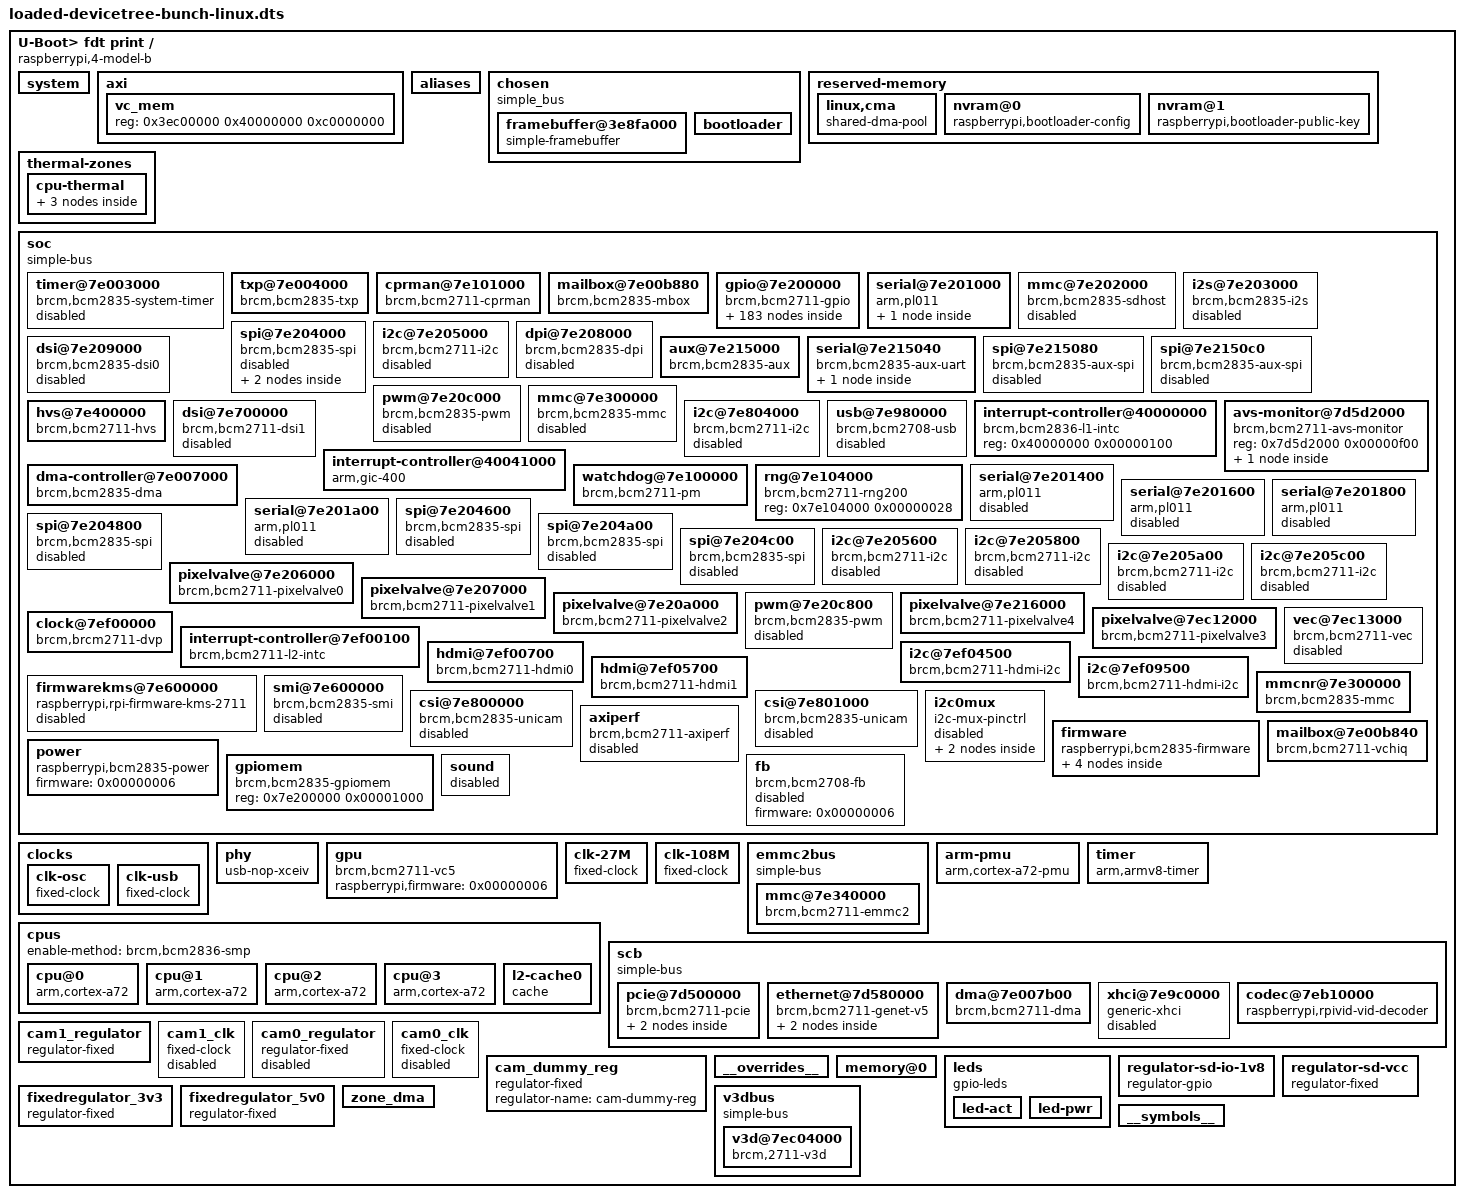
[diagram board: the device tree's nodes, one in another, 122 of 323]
U-Boot> fdt print
/ {
	memreserve = <0x30000000 0x10000000>;
	serial-number = "10000000747f32dc";
	compatible = "raspberrypi,4-model-b", "brcm,bcm2711";
	model = "Raspberry Pi 4 Model B Rev 1.4";
	#address-cells = <0x00000002>;
	#size-cells = <0x00000001>;
	interrupt-parent = <0x00000001>;
	system {
		linux,serial = <0x10000000 0x747f32dc>;
		linux,revision = <0x00c03114>;
	};
	axi {
		vc_mem {
			reg = <0x3ec00000 0x40000000 0xc0000000>;
		};
	};
	aliases {
		display0 = "/chosen/framebuffer@3e8fa000";
		serial0 = "/soc/serial@7e215040";
		serial1 = "/soc/serial@7e201000";
		emmc2bus = "/emmc2bus";
		ethernet0 = "/scb/ethernet@7d580000";
		pcie0 = "/scb/pcie@7d500000";
		blconfig = "/reserved-memory/nvram@0";
		blpubkey = "/reserved-memory/nvram@1";
		bluetooth = "/soc/serial@7e201000/bluetooth";
		aux = "/soc/aux@7e215000";
		sound = "/soc/sound";
		soc = "/soc";
		dma = "/soc/dma-controller@7e007000";
		watchdog = "/soc/watchdog@7e100000";
		random = "/soc/rng@7e104000";
		mailbox = "/soc/mailbox@7e00b880";
		gpio = "/soc/gpio@7e200000";
		uart0 = "/soc/serial@7e201000";
		uart1 = "/soc/serial@7e215040";
		sdhost = "/soc/mmc@7e202000";
		mmc = "/soc/mmc@7e300000";
		mmc1 = "/soc/mmcnr@7e300000";
		mmc0 = "/emmc2bus/mmc@7e340000";
		i2s = "/soc/i2s@7e203000";
		i2c0 = "/soc/i2c0mux/i2c@0";
		i2c1 = "/soc/i2c@7e804000";
		i2c10 = "/soc/i2c0mux/i2c@1";
		i2c = "/soc/i2c@7e804000";
		spi0 = "/soc/spi@7e204000";
		spi1 = "/soc/spi@7e215080";
		spi2 = "/soc/spi@7e2150c0";
		usb = "/soc/usb@7e980000";
		leds = "/leds";
		fb = "/soc/fb";
		thermal = "/soc/avs-monitor@7d5d2000/thermal";
		axiperf = "/soc/axiperf";
		uart2 = "/soc/serial@7e201400";
		uart3 = "/soc/serial@7e201600";
		uart4 = "/soc/serial@7e201800";
		uart5 = "/soc/serial@7e201a00";
		serial2 = "/soc/serial@7e201400";
		serial3 = "/soc/serial@7e201600";
		serial4 = "/soc/serial@7e201800";
		serial5 = "/soc/serial@7e201a00";
		mmc2 = "/soc/mmc@7e202000";
		i2c3 = "/soc/i2c@7e205600";
		i2c4 = "/soc/i2c@7e205800";
		i2c5 = "/soc/i2c@7e205a00";
		i2c6 = "/soc/i2c@7e205c00";
		i2c20 = "/soc/i2c@7ef04500";
		i2c21 = "/soc/i2c@7ef09500";
		spi3 = "/soc/spi@7e204600";
		spi4 = "/soc/spi@7e204800";
		spi5 = "/soc/spi@7e204a00";
		spi6 = "/soc/spi@7e204c00";
		phandle = <0x0000004f>;
	};
	chosen {
		ranges;
		#size-cells = <0x00000001>;
		#address-cells = <0x00000001>;
		compatible = "simple_bus";
		rng-seed = <0xc933548e 0xe2b80edd 0x7d824fa1 0x4c1fe433 0xff39cf23 0x2dc1764e 0x122f8091 0x8457ae2d 0x51d78ceb 0x2d145350 0x8de2d845 0x6ad47641 0xa8cb3f6f 0x5a67c199 0x287e0ceb 0x9471c304>;
		kaslr-seed = <0xa21e5f1d 0x71a5401c>;
		os_prefix = [00];
		overlay_prefix = "overlays/";
		rpi-boardrev-ext = <0x00000000>;
		log = <0x3ff80000 0x0007ffe0>;
		stdout-path = "serial0:115200n8";
		bootargs = "coherent_pool=1M 8250.nr_uarts=1 snd_bcm2835.enable_headphones=0 snd_bcm2835.enable_hdmi=0 video=HDMI-A-1:1024x768M@70 smsc95xx.macaddr=E4:5F:01:60:B9:C2 vc_mem.mem_base=0x3ec00000 vc_mem.mem_size=0x40000000  dwc_otg.lpm_enable=0 console=ttyS0,115200  net.ifnames=0";
		phandle = <0x00000050>;
		framebuffer@3e8fa000 {
			status = "okay";
			compatible = "simple-framebuffer";
			format = "a8r8g8b8";
			stride = <0x00001000>;
			height = <0x00000300>;
			width = <0x00000400>;
			reg = <0x3e8fa000 0x00300000>;
		};
		bootloader {
			boot-mode = <0x00000001>;
			version = "0b7b6f28b0a25311e6d75518aec0e29ecfb36ec0";
			capabilities = <0x0000007f>;
			update-timestamp = <0x6628b441>;
			build-timestamp = <0x661fc5d8>;
			tryboot = <0x00000000>;
			rsts = <0x00001000>;
			partition = <0x00000000>;
		};
	};
	reserved-memory {
		#address-cells = <0x00000002>;
		#size-cells = <0x00000001>;
		ranges;
		phandle = <0x00000056>;
		linux,cma {
			compatible = "shared-dma-pool";
			size = <0x20000000>;
			reusable;
			linux,cma-default;
			alloc-ranges = <0x00000000 0x00000000 0x30000000>;
			phandle = <0x00000057>;
		};
		nvram@0 {
			compatible = "raspberrypi,bootloader-config", "nvmem-rmem";
			#address-cells = <0x00000001>;
			#size-cells = <0x00000001>;
			reg = <0x00000000 0x3ef64640 0x00000036>;
			no-map;
			status = "okay";
			phandle = <0x00000058>;
		};
		nvram@1 {
			compatible = "raspberrypi,bootloader-public-key", "nvmem-rmem";
			#address-cells = <0x00000001>;
			#size-cells = <0x00000001>;
			reg = <0x00000000 0x3ef64400 0x00000200>;
			no-map;
			status = "okay";
			phandle = <0x00000059>;
		};
	};
	thermal-zones {
		cpu-thermal {
			polling-delay-passive = <0x00000000>;
			polling-delay = <0x000003e8>;
			coefficients = <0xfffffe19 0x000641b8>;
			thermal-sensors = <0x00000002>;
			phandle = <0x0000005a>;
			trips {
				phandle = <0x0000005b>;
				cpu-crit {
					temperature = <0x0001adb0>;
					hysteresis = <0x00000000>;
					type = "critical";
				};
			};
			cooling-maps {
				phandle = <0x0000005c>;
			};
		};
	};
	soc {
		compatible = "simple-bus";
		#address-cells = <0x00000001>;
		#size-cells = <0x00000001>;
		ranges = <0x7e000000 0x00000000 0xfe000000 0x01800000 0x7c000000 0x00000000 0xfc000000 0x02000000 0x40000000 0x00000000 0xff800000 0x00800000>;
		dma-ranges = <0xc0000000 0x00000000 0x00000000 0x40000000 0x7c000000 0x00000000 0xfc000000 0x03800000>;
		phandle = <0x0000005d>;
		timer@7e003000 {
			compatible = "brcm,bcm2835-system-timer";
			reg = <0x7e003000 0x00001000>;
			interrupts = <0x00000000 0x00000040 0x00000004 0x00000000 0x00000041 0x00000004 0x00000000 0x00000042 0x00000004 0x00000000 0x00000043 0x00000004>;
			clock-frequency = <0x000f4240>;
			status = "disabled";
			phandle = <0x0000005e>;
		};
		txp@7e004000 {
			compatible = "brcm,bcm2835-txp";
			reg = <0x7e004000 0x00000020>;
			interrupts = <0x00000000 0x0000004b 0x00000004>;
			status = "okay";
			phandle = <0x0000005f>;
		};
		cprman@7e101000 {
			compatible = "brcm,bcm2711-cprman";
			#clock-cells = <0x00000001>;
			reg = <0x7e101000 0x00002000>;
			clocks = <0x00000003 0x00000004 0x00000000 0x00000004 0x00000001 0x00000004 0x00000002 0x00000005 0x00000000 0x00000005 0x00000001 0x00000005 0x00000002>;
			firmware = <0x00000006>;
			phandle = <0x00000008>;
		};
		mailbox@7e00b880 {
			compatible = "brcm,bcm2835-mbox";
			reg = <0x7e00b880 0x00000040>;
			interrupts = <0x00000000 0x00000021 0x00000004>;
			#mbox-cells = <0x00000000>;
			phandle = <0x00000035>;
		};
		gpio@7e200000 {
			compatible = "brcm,bcm2711-gpio";
			reg = <0x7e200000 0x000000b4>;
			interrupts = <0x00000000 0x00000071 0x00000004 0x00000000 0x00000072 0x00000004>;
			gpio-controller;
			#gpio-cells = <0x00000002>;
			interrupt-controller;
			#interrupt-cells = <0x00000002>;
			gpio-ranges = <0x00000007 0x00000000 0x00000000 0x0000003a>;
			gpio-line-names = "ID_SDA", "ID_SCL", "GPIO2", "GPIO3", "GPIO4", "GPIO5", "GPIO6", "GPIO7", "GPIO8", "GPIO9", "GPIO10", "GPIO11", "GPIO12", "GPIO13", "GPIO14", "GPIO15", "GPIO16", "GPIO17", "GPIO18", "GPIO19", "GPIO20", "GPIO21", "GPIO22", "GPIO23", "GPIO24", "GPIO25", "GPIO26", "GPIO27", "RGMII_MDIO", "RGMIO_MDC", "CTS0", "RTS0", "TXD0", "RXD0", "SD1_CLK", "SD1_CMD", "SD1_DATA0", "SD1_DATA1", "SD1_DATA2", "SD1_DATA3", "PWM0_MISO", "PWM1_MOSI", "STATUS_LED_G_CLK", "SPIFLASH_CE_N", "SDA0", "SCL0", "RGMII_RXCLK", "RGMII_RXCTL", "RGMII_RXD0", "RGMII_RXD1", "RGMII_RXD2", "RGMII_RXD3", "RGMII_TXCLK", "RGMII_TXCTL", "RGMII_TXD0", "RGMII_TXD1", "RGMII_TXD2", "RGMII_TXD3";
			phandle = <0x00000007>;
			dpi-gpio0 {
				brcm,pins = <0x00000000 0x00000001 0x00000002 0x00000003 0x00000004 0x00000005 0x00000006 0x00000007 0x00000008 0x00000009 0x0000000a 0x0000000b 0x0000000c 0x0000000d 0x0000000e 0x0000000f 0x00000010 0x00000011 0x00000012 0x00000013 0x00000014 0x00000015 0x00000016 0x00000017 0x00000018 0x00000019 0x0000001a 0x0000001b>;
				brcm,function = <0x00000006>;
				phandle = <0x00000060>;
			};
			emmc-gpio22 {
				brcm,pins = <0x00000016 0x00000017 0x00000018 0x00000019 0x0000001a 0x0000001b>;
				brcm,function = <0x00000007>;
				phandle = <0x00000061>;
			};
			emmc-gpio34 {
				brcm,pins = <0x00000022 0x00000023 0x00000024 0x00000025 0x00000026 0x00000027>;
				brcm,function = <0x00000007>;
				brcm,pull = <0x00000000 0x00000002 0x00000002 0x00000002 0x00000002 0x00000002>;
				phandle = <0x00000062>;
			};
			emmc-gpio48 {
				brcm,pins = <0x00000030 0x00000031 0x00000032 0x00000033 0x00000034 0x00000035>;
				brcm,function = <0x00000007>;
				phandle = <0x00000013>;
			};
			gpclk0-gpio4 {
				brcm,pins = <0x00000004>;
				brcm,function = <0x00000004>;
				phandle = <0x00000063>;
			};
			gpclk1-gpio5 {
				brcm,pins = <0x00000005>;
				brcm,function = <0x00000004>;
				phandle = <0x00000064>;
			};
			gpclk1-gpio42 {
				brcm,pins = <0x0000002a>;
				brcm,function = <0x00000004>;
				phandle = <0x00000065>;
			};
			gpclk1-gpio44 {
				brcm,pins = <0x0000002c>;
				brcm,function = <0x00000004>;
				phandle = <0x00000066>;
			};
			gpclk2-gpio6 {
				brcm,pins = <0x00000006>;
				brcm,function = <0x00000004>;
				phandle = <0x00000067>;
			};
			gpclk2-gpio43 {
				brcm,pins = <0x0000002b>;
				brcm,function = <0x00000004>;
				brcm,pull = <0x00000000>;
				phandle = <0x00000068>;
			};
			i2c0if-gpio0 {
				brcm,pins = <0x00000000 0x00000001>;
				brcm,function = <0x00000004>;
				phandle = <0x00000033>;
			};
			i2c0if-gpio28 {
				brcm,pins = <0x0000001c 0x0000001d>;
				brcm,function = <0x00000004>;
				phandle = <0x00000069>;
			};
			i2c0if-gpio44 {
				brcm,pins = <0x0000002c 0x0000002d>;
				brcm,function = <0x00000005>;
				phandle = <0x00000034>;
			};
			i2c1-gpio2 {
				brcm,pins = <0x00000002 0x00000003>;
				brcm,function = <0x00000004>;
				phandle = <0x0000006a>;
			};
			i2c1-gpio44 {
				brcm,pins = <0x0000002c 0x0000002d>;
				brcm,function = <0x00000006>;
				phandle = <0x0000006b>;
			};
			jtag-gpio22 {
				brcm,pins = <0x00000016 0x00000017 0x00000018 0x00000019 0x0000001a 0x0000001b>;
				brcm,function = <0x00000003>;
				phandle = <0x0000006c>;
			};
			pcm-gpio18 {
				brcm,pins = <0x00000012 0x00000013 0x00000014 0x00000015>;
				brcm,function = <0x00000004>;
				phandle = <0x0000006d>;
			};
			pcm-gpio28 {
				brcm,pins = <0x0000001c 0x0000001d 0x0000001e 0x0000001f>;
				brcm,function = <0x00000006>;
				phandle = <0x0000006e>;
			};
			sdhost-gpio48 {
				brcm,pins = <0x00000030 0x00000031 0x00000032 0x00000033 0x00000034 0x00000035>;
				brcm,function = <0x00000004>;
				phandle = <0x0000006f>;
			};
			spi0-gpio7 {
				brcm,pins = <0x00000007 0x00000008 0x00000009 0x0000000a 0x0000000b>;
				brcm,function = <0x00000004>;
				phandle = <0x00000070>;
			};
			spi0-gpio35 {
				brcm,pins = <0x00000023 0x00000024 0x00000025 0x00000026 0x00000027>;
				brcm,function = <0x00000004>;
				phandle = <0x00000071>;
			};
			spi1-gpio16 {
				brcm,pins = <0x00000010 0x00000011 0x00000012 0x00000013 0x00000014 0x00000015>;
				brcm,function = <0x00000003>;
				phandle = <0x00000072>;
			};
			spi2-gpio40 {
				brcm,pins = <0x00000028 0x00000029 0x0000002a 0x0000002b 0x0000002c 0x0000002d>;
				brcm,function = <0x00000003>;
				phandle = <0x00000073>;
			};
			uart0-gpio14 {
				brcm,pins = <0x0000000e 0x0000000f>;
				brcm,function = <0x00000004>;
				phandle = <0x00000074>;
			};
			uart0-ctsrts-gpio16 {
				brcm,pins = <0x00000010 0x00000011>;
				brcm,function = <0x00000007>;
				phandle = <0x00000075>;
			};
			uart0-ctsrts-gpio30 {
				brcm,pins = <0x0000001e 0x0000001f>;
				brcm,function = <0x00000007>;
				brcm,pull = <0x00000002 0x00000000>;
				phandle = <0x00000076>;
			};
			uart0-gpio32 {
				brcm,pins = <0x00000020 0x00000021>;
				brcm,function = <0x00000007>;
				brcm,pull = <0x00000000 0x00000002>;
				phandle = <0x00000077>;
			};
			uart0-gpio36 {
				brcm,pins = <0x00000024 0x00000025>;
				brcm,function = <0x00000006>;
				phandle = <0x00000078>;
			};
			uart0-ctsrts-gpio38 {
				brcm,pins = <0x00000026 0x00000027>;
				brcm,function = <0x00000006>;
				phandle = <0x00000079>;
			};
			uart1-gpio14 {
				brcm,pins = <0x0000000e 0x0000000f>;
				brcm,function = <0x00000002>;
				phandle = <0x0000007a>;
			};
			uart1-ctsrts-gpio16 {
				brcm,pins = <0x00000010 0x00000011>;
				brcm,function = <0x00000002>;
				phandle = <0x0000007b>;
			};
			uart1-gpio32 {
				brcm,pins = <0x00000020 0x00000021>;
				brcm,function = <0x00000002>;
				phandle = <0x0000007c>;
			};
			uart1-ctsrts-gpio30 {
				brcm,pins = <0x0000001e 0x0000001f>;
				brcm,function = <0x00000002>;
				phandle = <0x0000007d>;
			};
			uart1-gpio40 {
				brcm,pins = <0x00000028 0x00000029>;
				brcm,function = <0x00000002>;
				phandle = <0x0000007e>;
			};
			uart1-ctsrts-gpio42 {
				brcm,pins = <0x0000002a 0x0000002b>;
				brcm,function = <0x00000002>;
				phandle = <0x0000007f>;
			};
			gpclk0-gpio49 {
				phandle = <0x00000080>;
				pin-gpclk {
					pins = "gpio49";
					function = "alt1";
					bias-disable;
				};
			};
			gpclk1-gpio50 {
				phandle = <0x00000081>;
				pin-gpclk {
					pins = "gpio50";
					function = "alt1";
					bias-disable;
				};
			};
			gpclk2-gpio51 {
				phandle = <0x00000082>;
				pin-gpclk {
					pins = "gpio51";
					function = "alt1";
					bias-disable;
				};
			};
			i2c0if-gpio46 {
				phandle = <0x00000083>;
				pin-sda {
					function = "alt0";
					pins = "gpio46";
					bias-pull-up;
				};
				pin-scl {
					function = "alt0";
					pins = "gpio47";
					bias-disable;
				};
			};
			i2c1-gpio46 {
				phandle = <0x00000084>;
				pin-sda {
					function = "alt1";
					pins = "gpio46";
					bias-pull-up;
				};
				pin-scl {
					function = "alt1";
					pins = "gpio47";
					bias-disable;
				};
			};
			i2c3-gpio2 {
				phandle = <0x00000085>;
				pin-sda {
					function = "alt5";
					pins = "gpio2";
					bias-pull-up;
				};
				pin-scl {
					function = "alt5";
					pins = "gpio3";
					bias-disable;
				};
			};
			i2c3-gpio4 {
				phandle = <0x00000086>;
				pin-sda {
					function = "alt5";
					pins = "gpio4";
					bias-pull-up;
				};
				pin-scl {
					function = "alt5";
					pins = "gpio5";
					bias-disable;
				};
			};
			i2c4-gpio6 {
				phandle = <0x00000087>;
				pin-sda {
					function = "alt5";
					pins = "gpio6";
					bias-pull-up;
				};
				pin-scl {
					function = "alt5";
					pins = "gpio7";
					bias-disable;
				};
			};
			i2c4-gpio8 {
				phandle = <0x00000088>;
				pin-sda {
					function = "alt5";
					pins = "gpio8";
					bias-pull-up;
				};
				pin-scl {
					function = "alt5";
					pins = "gpio9";
					bias-disable;
				};
			};
			i2c5-gpio10 {
				phandle = <0x00000089>;
				pin-sda {
					function = "alt5";
					pins = "gpio10";
					bias-pull-up;
				};
				pin-scl {
					function = "alt5";
					pins = "gpio11";
					bias-disable;
				};
			};
			i2c5-gpio12 {
				phandle = <0x0000008a>;
				pin-sda {
					function = "alt5";
					pins = "gpio12";
					bias-pull-up;
				};
				pin-scl {
					function = "alt5";
					pins = "gpio13";
					bias-disable;
				};
			};
			i2c6-gpio0 {
				phandle = <0x0000008b>;
				pin-sda {
					function = "alt5";
					pins = "gpio0";
					bias-pull-up;
				};
				pin-scl {
					function = "alt5";
					pins = "gpio1";
					bias-disable;
				};
			};
			i2c6-gpio22 {
				phandle = <0x0000008c>;
				pin-sda {
					function = "alt5";
					pins = "gpio22";
					bias-pull-up;
				};
				pin-scl {
					function = "alt5";
					pins = "gpio23";
					bias-disable;
				};
			};
			i2c-slave-gpio8 {
				phandle = <0x0000008d>;
				pins-i2c-slave {
					pins = "gpio8", "gpio9", "gpio10", "gpio11";
					function = "alt3";
				};
			};
			jtag-gpio48 {
				phandle = <0x0000008e>;
				pins-jtag {
					pins = "gpio48", "gpio49", "gpio50", "gpio51", "gpio52", "gpio53";
					function = "alt4";
				};
			};
			mii-gpio28 {
				phandle = <0x0000008f>;
				pins-mii {
					pins = "gpio28", "gpio29", "gpio30", "gpio31";
					function = "alt4";
				};
			};
			mii-gpio36 {
				phandle = <0x00000090>;
				pins-mii {
					pins = "gpio36", "gpio37", "gpio38", "gpio39";
					function = "alt5";
				};
			};
			pcm-gpio50 {
				phandle = <0x00000091>;
				pins-pcm {
					pins = "gpio50", "gpio51", "gpio52", "gpio53";
					function = "alt2";
				};
			};
			pwm0-0-gpio12 {
				phandle = <0x00000092>;
				pin-pwm {
					pins = "gpio12";
					function = "alt0";
					bias-disable;
				};
			};
			pwm0-0-gpio18 {
				phandle = <0x00000093>;
				pin-pwm {
					pins = "gpio18";
					function = "alt5";
					bias-disable;
				};
			};
			pwm1-0-gpio40 {
				phandle = <0x00000028>;
				pin-pwm {
					pins = "gpio40";
					function = "alt0";
					bias-disable;
				};
			};
			pwm0-1-gpio13 {
				phandle = <0x00000094>;
				pin-pwm {
					pins = "gpio13";
					function = "alt0";
					bias-disable;
				};
			};
			pwm0-1-gpio19 {
				phandle = <0x00000095>;
				pin-pwm {
					pins = "gpio19";
					function = "alt5";
					bias-disable;
				};
			};
			pwm1-1-gpio41 {
				phandle = <0x00000029>;
				pin-pwm {
					pins = "gpio41";
					function = "alt0";
					bias-disable;
				};
			};
			pwm0-1-gpio45 {
				phandle = <0x00000096>;
				pin-pwm {
					pins = "gpio45";
					function = "alt0";
					bias-disable;
				};
			};
			pwm0-0-gpio52 {
				phandle = <0x00000097>;
				pin-pwm {
					pins = "gpio52";
					function = "alt1";
					bias-disable;
				};
			};
			pwm0-1-gpio53 {
				phandle = <0x00000098>;
				pin-pwm {
					pins = "gpio53";
					function = "alt1";
					bias-disable;
				};
			};
			rgmii-gpio35 {
				phandle = <0x00000099>;
				pin-start-stop {
					pins = "gpio35";
					function = "alt4";
				};
				pin-rx-ok {
					pins = "gpio36";
					function = "alt4";
				};
			};
			rgmii-irq-gpio34 {
				phandle = <0x0000009a>;
				pin-irq {
					pins = "gpio34";
					function = "alt5";
				};
			};
			rgmii-irq-gpio39 {
				phandle = <0x0000009b>;
				pin-irq {
					pins = "gpio39";
					function = "alt4";
				};
			};
			rgmii-mdio-gpio28 {
				phandle = <0x0000009c>;
				pins-mdio {
					pins = "gpio28", "gpio29";
					function = "alt5";
				};
			};
			rgmii-mdio-gpio37 {
				phandle = <0x0000009d>;
				pins-mdio {
					pins = "gpio37", "gpio38";
					function = "alt4";
				};
			};
			spi0-gpio46 {
				phandle = <0x0000009e>;
				pins-spi {
					pins = "gpio46", "gpio47", "gpio48", "gpio49";
					function = "alt2";
				};
			};
			spi2-gpio46 {
				phandle = <0x0000009f>;
				pins-spi {
					pins = "gpio46", "gpio47", "gpio48", "gpio49", "gpio50";
					function = "alt5";
				};
			};
			spi3-gpio0 {
				phandle = <0x000000a0>;
				pins-spi {
					pins = "gpio0", "gpio1", "gpio2", "gpio3";
					function = "alt3";
				};
			};
			spi4-gpio4 {
				phandle = <0x000000a1>;
				pins-spi {
					pins = "gpio4", "gpio5", "gpio6", "gpio7";
					function = "alt3";
				};
			};
			spi5-gpio12 {
				phandle = <0x000000a2>;
				pins-spi {
					pins = "gpio12", "gpio13", "gpio14", "gpio15";
					function = "alt3";
				};
			};
			spi6-gpio18 {
				phandle = <0x000000a3>;
				pins-spi {
					pins = "gpio18", "gpio19", "gpio20", "gpio21";
					function = "alt3";
				};
			};
			uart2-gpio0 {
				phandle = <0x000000a4>;
				pin-tx {
					pins = "gpio0";
					function = "alt4";
					bias-disable;
				};
				pin-rx {
					pins = "gpio1";
					function = "alt4";
					bias-pull-up;
				};
			};
			uart2-ctsrts-gpio2 {
				phandle = <0x000000a5>;
				pin-cts {
					pins = "gpio2";
					function = "alt4";
					bias-pull-up;
				};
				pin-rts {
					pins = "gpio3";
					function = "alt4";
					bias-disable;
				};
			};
			uart3-gpio4 {
				phandle = <0x000000a6>;
				pin-tx {
					pins = "gpio4";
					function = "alt4";
					bias-disable;
				};
				pin-rx {
					pins = "gpio5";
					function = "alt4";
					bias-pull-up;
				};
			};
			uart3-ctsrts-gpio6 {
				phandle = <0x000000a7>;
				pin-cts {
					pins = "gpio6";
					function = "alt4";
					bias-pull-up;
				};
				pin-rts {
					pins = "gpio7";
					function = "alt4";
					bias-disable;
				};
			};
			uart4-gpio8 {
				phandle = <0x000000a8>;
				pin-tx {
					pins = "gpio8";
					function = "alt4";
					bias-disable;
				};
				pin-rx {
					pins = "gpio9";
					function = "alt4";
					bias-pull-up;
				};
			};
			uart4-ctsrts-gpio10 {
				phandle = <0x000000a9>;
				pin-cts {
					pins = "gpio10";
					function = "alt4";
					bias-pull-up;
				};
				pin-rts {
					pins = "gpio11";
					function = "alt4";
					bias-disable;
				};
			};
			uart5-gpio12 {
				phandle = <0x000000aa>;
				pin-tx {
					pins = "gpio12";
					function = "alt4";
					bias-disable;
				};
				pin-rx {
					pins = "gpio13";
					function = "alt4";
					bias-pull-up;
				};
			};
			uart5-ctsrts-gpio14 {
				phandle = <0x000000ab>;
				pin-cts {
					pins = "gpio14";
					function = "alt4";
					bias-pull-up;
				};
				pin-rts {
					pins = "gpio15";
					function = "alt4";
					bias-disable;
				};
			};
			dpi_18bit_cpadhi_gpio0 {
				brcm,pins = <0x00000000 0x00000001 0x00000002 0x00000003 0x00000004 0x00000005 0x00000006 0x00000007 0x00000008 0x00000009 0x0000000c 0x0000000d 0x0000000e 0x0000000f 0x00000010 0x00000011 0x00000014 0x00000015 0x00000016 0x00000017 0x00000018 0x00000019>;
				brcm,function = <0x00000006>;
				brcm,pull = <0x00000000>;
				phandle = <0x000000ac>;
			};
			dpi_18bit_cpadhi_gpio2 {
				brcm,pins = <0x00000002 0x00000003 0x00000004 0x00000005 0x00000006 0x00000007 0x00000008 0x00000009 0x0000000c 0x0000000d 0x0000000e 0x0000000f 0x00000010 0x00000011 0x00000014 0x00000015 0x00000016 0x00000017 0x00000018 0x00000019>;
				brcm,function = <0x00000006>;
				phandle = <0x000000ad>;
			};
			dpi_18bit_gpio0 {
				brcm,pins = <0x00000000 0x00000001 0x00000002 0x00000003 0x00000004 0x00000005 0x00000006 0x00000007 0x00000008 0x00000009 0x0000000a 0x0000000b 0x0000000c 0x0000000d 0x0000000e 0x0000000f 0x00000010 0x00000011 0x00000012 0x00000013 0x00000014 0x00000015>;
				brcm,function = <0x00000006>;
				phandle = <0x000000ae>;
			};
			dpi_18bit_gpio2 {
				brcm,pins = <0x00000002 0x00000003 0x00000004 0x00000005 0x00000006 0x00000007 0x00000008 0x00000009 0x0000000a 0x0000000b 0x0000000c 0x0000000d 0x0000000e 0x0000000f 0x00000010 0x00000011 0x00000012 0x00000013 0x00000014 0x00000015>;
				brcm,function = <0x00000006>;
				phandle = <0x000000af>;
			};
			dpi_16bit_gpio0 {
				brcm,pins = <0x00000000 0x00000001 0x00000002 0x00000003 0x00000004 0x00000005 0x00000006 0x00000007 0x00000008 0x00000009 0x0000000a 0x0000000b 0x0000000c 0x0000000d 0x0000000e 0x0000000f 0x00000010 0x00000011 0x00000012 0x00000013>;
				brcm,function = <0x00000006>;
				phandle = <0x000000b0>;
			};
			dpi_16bit_gpio2 {
				brcm,pins = <0x00000002 0x00000003 0x00000004 0x00000005 0x00000006 0x00000007 0x00000008 0x00000009 0x0000000a 0x0000000b 0x0000000c 0x0000000d 0x0000000e 0x0000000f 0x00000010 0x00000011 0x00000012 0x00000013>;
				brcm,function = <0x00000006>;
				phandle = <0x000000b1>;
			};
			dpi_16bit_cpadhi_gpio0 {
				brcm,pins = <0x00000000 0x00000001 0x00000002 0x00000003 0x00000004 0x00000005 0x00000006 0x00000007 0x00000008 0x0000000c 0x0000000d 0x0000000e 0x0000000f 0x00000010 0x00000011 0x00000014 0x00000015 0x00000016 0x00000017 0x00000018>;
				brcm,function = <0x00000006>;
				phandle = <0x000000b2>;
			};
			dpi_16bit_cpadhi_gpio2 {
				brcm,pins = <0x00000002 0x00000003 0x00000004 0x00000005 0x00000006 0x00000007 0x00000008 0x0000000c 0x0000000d 0x0000000e 0x0000000f 0x00000010 0x00000011 0x00000014 0x00000015 0x00000016 0x00000017 0x00000018>;
				brcm,function = <0x00000006>;
				phandle = <0x000000b3>;
			};
			gpioout {
				brcm,pins = <0x00000006>;
				brcm,function = <0x00000001>;
				phandle = <0x000000b4>;
			};
			alt0 {
				brcm,pins = <0x00000004 0x00000005 0x00000007 0x00000008 0x00000009 0x0000000a 0x0000000b>;
				brcm,function = <0x00000004>;
				phandle = <0x000000b5>;
			};
			spi0_pins {
				brcm,pins = <0x00000009 0x0000000a 0x0000000b>;
				brcm,function = <0x00000004>;
				phandle = <0x0000000e>;
			};
			spi0_cs_pins {
				brcm,pins = <0x00000008 0x00000007>;
				brcm,function = <0x00000001>;
				phandle = <0x0000000f>;
			};
			spi3_pins {
				brcm,pins = <0x00000001 0x00000002 0x00000003>;
				brcm,function = <0x00000007>;
				phandle = <0x0000001c>;
			};
			spi3_cs_pins {
				brcm,pins = <0x00000000 0x00000018>;
				brcm,function = <0x00000001>;
				phandle = <0x0000001d>;
			};
			spi4_pins {
				brcm,pins = <0x00000005 0x00000006 0x00000007>;
				brcm,function = <0x00000007>;
				phandle = <0x0000001e>;
			};
			spi4_cs_pins {
				brcm,pins = <0x00000004 0x00000019>;
				brcm,function = <0x00000001>;
				phandle = <0x0000001f>;
			};
			spi5_pins {
				brcm,pins = <0x0000000d 0x0000000e 0x0000000f>;
				brcm,function = <0x00000007>;
				phandle = <0x00000020>;
			};
			spi5_cs_pins {
				brcm,pins = <0x0000000c 0x0000001a>;
				brcm,function = <0x00000001>;
				phandle = <0x00000021>;
			};
			spi6_pins {
				brcm,pins = <0x00000013 0x00000014 0x00000015>;
				brcm,function = <0x00000007>;
				phandle = <0x00000022>;
			};
			spi6_cs_pins {
				brcm,pins = <0x00000012 0x0000001b>;
				brcm,function = <0x00000001>;
				phandle = <0x00000023>;
			};
			i2c0 {
				brcm,pins = <0x00000000 0x00000001>;
				brcm,function = <0x00000004>;
				brcm,pull = <0x00000002>;
				phandle = <0x000000b6>;
			};
			i2c1 {
				brcm,pins = <0x00000002 0x00000003>;
				brcm,function = <0x00000004>;
				brcm,pull = <0x00000002>;
				phandle = <0x00000015>;
			};
			i2c3 {
				brcm,pins = <0x00000004 0x00000005>;
				brcm,function = <0x00000002>;
				brcm,pull = <0x00000002>;
				phandle = <0x00000024>;
			};
			i2c4 {
				brcm,pins = <0x00000008 0x00000009>;
				brcm,function = <0x00000002>;
				brcm,pull = <0x00000002>;
				phandle = <0x00000025>;
			};
			i2c5 {
				brcm,pins = <0x0000000c 0x0000000d>;
				brcm,function = <0x00000002>;
				brcm,pull = <0x00000002>;
				phandle = <0x00000026>;
			};
			i2c6 {
				brcm,pins = <0x00000016 0x00000017>;
				brcm,function = <0x00000002>;
				brcm,pull = <0x00000002>;
				phandle = <0x00000027>;
			};
			i2s {
				brcm,pins = <0x00000012 0x00000013 0x00000014 0x00000015>;
				brcm,function = <0x00000004>;
				phandle = <0x0000000d>;
			};
			sdio_pins {
				brcm,pins = <0x00000022 0x00000023 0x00000024 0x00000025 0x00000026 0x00000027>;
				brcm,function = <0x00000007>;
				brcm,pull = <0x00000000 0x00000002 0x00000002 0x00000002 0x00000002 0x00000002>;
				phandle = <0x00000031>;
			};
			uart2_pins {
				brcm,pins = <0x00000000 0x00000001>;
				brcm,function = <0x00000003>;
				brcm,pull = <0x00000000 0x00000002>;
				phandle = <0x00000018>;
			};
			uart3_pins {
				brcm,pins = <0x00000004 0x00000005>;
				brcm,function = <0x00000003>;
				brcm,pull = <0x00000000 0x00000002>;
				phandle = <0x00000019>;
			};
			uart4_pins {
				brcm,pins = <0x00000008 0x00000009>;
				brcm,function = <0x00000003>;
				brcm,pull = <0x00000000 0x00000002>;
				phandle = <0x0000001a>;
			};
			uart5_pins {
				brcm,pins = <0x0000000c 0x0000000d>;
				brcm,function = <0x00000003>;
				brcm,pull = <0x00000000 0x00000002>;
				phandle = <0x0000001b>;
			};
			bt_pins {
				brcm,pins = "-";
				brcm,function = <0x00000000>;
				brcm,pull = <0x00000002>;
				phandle = <0x0000000a>;
			};
			uart0_pins {
				brcm,pins = <0x0000001e 0x0000001f 0x00000020 0x00000021>;
				brcm,function = <0x00000007>;
				brcm,pull = <0x00000002 0x00000000 0x00000000 0x00000002>;
				phandle = <0x00000009>;
			};
			uart1_pins {
				brcm,pins;
				brcm,function;
				brcm,pull;
				phandle = <0x00000012>;
			};
			uart1_bt_pins {
				brcm,pins = <0x00000020 0x00000021 0x0000001e 0x0000001f>;
				brcm,function = <0x00000002>;
				brcm,pull = <0x00000000 0x00000002 0x00000002 0x00000000>;
				phandle = <0x000000b7>;
			};
			audio_pins {
				brcm,pins = <0x00000028 0x00000029>;
				brcm,function = <0x00000004>;
				brcm,pull = <0x00000000>;
				phandle = <0x00000036>;
			};
		};
		serial@7e201000 {
			compatible = "arm,pl011", "arm,primecell";
			reg = <0x7e201000 0x00000200>;
			interrupts = <0x00000000 0x00000079 0x00000004>;
			clocks = <0x00000008 0x00000013 0x00000008 0x00000014>;
			clock-names = "uartclk", "apb_pclk";
			arm,primecell-periphid = <0x00241011>;
			status = "okay";
			cts-event-workaround;
			pinctrl-names = "default";
			pinctrl-0 = <0x00000009 0x0000000a>;
			uart-has-rtscts;
			skip-init;
			phandle = <0x00000043>;
			bluetooth {
				compatible = "brcm,bcm43438-bt";
				max-speed = <0x002dc6c0>;
				shutdown-gpios = <0x0000000b 0x00000000 0x00000000>;
				local-bd-address = [68 13 ca 01 5f e4];
				fallback-bd-address;
				status = "okay";
				phandle = <0x00000041>;
			};
		};
		mmc@7e202000 {
			compatible = "brcm,bcm2835-sdhost";
			reg = <0x7e202000 0x00000100>;
			interrupts = <0x00000000 0x00000078 0x00000004>;
			clocks = <0x00000008 0x00000014>;
			status = "disabled";
			dmas = <0x0000000c 0x2000000d>;
			dma-names = "rx-tx";
			bus-width = <0x00000004>;
			brcm,overclock-50 = <0x00000000>;
			brcm,pio-limit = <0x00000001>;
			firmware = <0x00000006>;
			phandle = <0x0000004b>;
		};
		i2s@7e203000 {
			compatible = "brcm,bcm2835-i2s";
			reg = <0x7e203000 0x00000024>;
			clocks = <0x00000008 0x0000001f>;
			status = "disabled";
			#sound-dai-cells = <0x00000000>;
			dmas = <0x0000000c 0x00000002 0x0000000c 0x00000003>;
			dma-names = "tx", "rx";
			pinctrl-names = "default";
			pinctrl-0 = <0x0000000d>;
			phandle = <0x00000045>;
		};
		spi@7e204000 {
			compatible = "brcm,bcm2835-spi";
			reg = <0x7e204000 0x00000200>;
			interrupts = <0x00000000 0x00000076 0x00000004>;
			clocks = <0x00000008 0x00000014>;
			#address-cells = <0x00000001>;
			#size-cells = <0x00000000>;
			status = "disabled";
			dmas = <0x0000000c 0x00000006 0x0000000c 0x00000007>;
			dma-names = "tx", "rx";
			pinctrl-names = "default";
			pinctrl-0 = <0x0000000e 0x0000000f>;
			cs-gpios = <0x00000007 0x00000008 0x00000001 0x00000007 0x00000007 0x00000001>;
			phandle = <0x00000046>;
			spidev@0 {
				compatible = "spidev";
				reg = <0x00000000>;
				#address-cells = <0x00000001>;
				#size-cells = <0x00000000>;
				spi-max-frequency = <0x07735940>;
				phandle = <0x000000b8>;
			};
			spidev@1 {
				compatible = "spidev";
				reg = <0x00000001>;
				#address-cells = <0x00000001>;
				#size-cells = <0x00000000>;
				spi-max-frequency = <0x07735940>;
				phandle = <0x000000b9>;
			};
		};
		i2c@7e205000 {
			compatible = "brcm,bcm2711-i2c", "brcm,bcm2835-i2c";
			reg = <0x7e205000 0x00000200>;
			interrupts = <0x00000000 0x00000075 0x00000004>;
			clocks = <0x00000008 0x00000014>;
			#address-cells = <0x00000001>;
			#size-cells = <0x00000000>;
			status = "disabled";
			clock-frequency = <0x000186a0>;
			phandle = <0x00000032>;
		};
		dpi@7e208000 {
			compatible = "brcm,bcm2835-dpi";
			reg = <0x7e208000 0x0000008c>;
			clocks = <0x00000008 0x00000014 0x00000008 0x0000002c>;
			clock-names = "core", "pixel";
			status = "disabled";
			phandle = <0x000000ba>;
		};
		dsi@7e209000 {
			compatible = "brcm,bcm2835-dsi0";
			reg = <0x7e209000 0x00000078>;
			interrupts = <0x00000000 0x00000064 0x00000004>;
			#address-cells = <0x00000001>;
			#size-cells = <0x00000000>;
			#clock-cells = <0x00000001>;
			clocks = <0x00000008 0x00000020 0x00000008 0x0000002f 0x00000008 0x00000031>;
			clock-names = "phy", "escape", "pixel";
			clock-output-names = "dsi0_byte", "dsi0_ddr2", "dsi0_ddr";
			status = "disabled";
			power-domains = <0x00000010 0x00000011>;
			phandle = <0x00000004>;
		};
		aux@7e215000 {
			compatible = "brcm,bcm2835-aux";
			#clock-cells = <0x00000001>;
			reg = <0x7e215000 0x00000008>;
			clocks = <0x00000008 0x00000014>;
			phandle = <0x00000011>;
		};
		serial@7e215040 {
			compatible = "brcm,bcm2835-aux-uart";
			reg = <0x7e215040 0x00000040>;
			interrupts = <0x00000000 0x0000005d 0x00000004>;
			clocks = <0x00000011 0x00000000>;
			status = "okay";
			pinctrl-names = "default";
			pinctrl-0 = <0x00000012>;
			skip-init;
			phandle = <0x00000044>;
			bluetooth {
				compatible = "brcm,bcm43438-bt";
				max-speed = <0x00038400>;
				shutdown-gpios = <0x0000000b 0x00000000 0x00000000>;
				local-bd-address = [00 00 00 00 00 00];
				fallback-bd-address;
				status = "disabled";
				phandle = <0x00000042>;
			};
		};
		spi@7e215080 {
			compatible = "brcm,bcm2835-aux-spi";
			reg = <0x7e215080 0x00000040>;
			interrupts = <0x00000000 0x0000005d 0x00000004>;
			clocks = <0x00000011 0x00000001>;
			#address-cells = <0x00000001>;
			#size-cells = <0x00000000>;
			status = "disabled";
			phandle = <0x000000bb>;
		};
		spi@7e2150c0 {
			compatible = "brcm,bcm2835-aux-spi";
			reg = <0x7e2150c0 0x00000040>;
			interrupts = <0x00000000 0x0000005d 0x00000004>;
			clocks = <0x00000011 0x00000002>;
			#address-cells = <0x00000001>;
			#size-cells = <0x00000000>;
			status = "disabled";
			phandle = <0x000000bc>;
		};
		pwm@7e20c000 {
			compatible = "brcm,bcm2835-pwm";
			reg = <0x7e20c000 0x00000028>;
			clocks = <0x00000008 0x0000001e>;
			assigned-clocks = <0x00000008 0x0000001e>;
			assigned-clock-rates = <0x02faf080>;
			#pwm-cells = <0x00000003>;
			status = "disabled";
			phandle = <0x000000bd>;
		};
		mmc@7e300000 {
			compatible = "brcm,bcm2835-mmc", "brcm,bcm2835-sdhci";
			reg = <0x7e300000 0x00000100>;
			interrupts = <0x00000000 0x0000007e 0x00000004>;
			clocks = <0x00000008 0x0000001c>;
			status = "disabled";
			pinctrl-names = "default";
			pinctrl-0 = <0x00000013>;
			bus-width = <0x00000004>;
			dmas = <0x0000000c 0x0000000b>;
			dma-names = "rx-tx";
			brcm,overclock-50 = <0x00000000>;
			phandle = <0x0000004c>;
		};
		hvs@7e400000 {
			compatible = "brcm,bcm2711-hvs";
			reg = <0x7e400000 0x00008000>;
			interrupts = <0x00000000 0x00000061 0x00000004>;
			status = "okay";
			clocks = <0x00000014 0x00000004>;
			phandle = <0x000000be>;
		};
		dsi@7e700000 {
			compatible = "brcm,bcm2711-dsi1";
			reg = <0x7e700000 0x0000008c>;
			interrupts = <0x00000000 0x0000006c 0x00000004>;
			#address-cells = <0x00000001>;
			#size-cells = <0x00000000>;
			#clock-cells = <0x00000001>;
			clocks = <0x00000008 0x00000023 0x00000008 0x00000030 0x00000008 0x00000032>;
			clock-names = "phy", "escape", "pixel";
			clock-output-names = "dsi1_byte", "dsi1_ddr2", "dsi1_ddr";
			status = "disabled";
			power-domains = <0x00000010 0x00000012>;
			phandle = <0x00000005>;
		};
		i2c@7e804000 {
			compatible = "brcm,bcm2711-i2c", "brcm,bcm2835-i2c";
			reg = <0x7e804000 0x00001000>;
			interrupts = <0x00000000 0x00000075 0x00000004>;
			clocks = <0x00000008 0x00000014>;
			#address-cells = <0x00000001>;
			#size-cells = <0x00000000>;
			status = "disabled";
			pinctrl-names = "default";
			pinctrl-0 = <0x00000015>;
			clock-frequency = <0x000186a0>;
			phandle = <0x00000048>;
		};
		usb@7e980000 {
			compatible = "brcm,bcm2708-usb";
			reg = <0x7e980000 0x00010000 0x7e00b200 0x00000200>;
			interrupts = <0x00000000 0x00000049 0x00000004 0x00000000 0x00000028 0x00000004>;
			#address-cells = <0x00000001>;
			#size-cells = <0x00000000>;
			clocks = <0x00000016>;
			clock-names = "otg";
			phys = <0x00000017>;
			phy-names = "usb2-phy";
			interrupt-names = "usb", "soft";
			power-domains = <0x00000010 0x00000006>;
			status = "disabled";
			phandle = <0x000000bf>;
		};
		interrupt-controller@40000000 {
			compatible = "brcm,bcm2836-l1-intc";
			reg = <0x40000000 0x00000100>;
			phandle = <0x000000c0>;
		};
		interrupt-controller@40041000 {
			interrupt-controller;
			#interrupt-cells = <0x00000003>;
			compatible = "arm,gic-400";
			reg = <0x40041000 0x00001000 0x40042000 0x00002000 0x40044000 0x00002000 0x40046000 0x00002000>;
			interrupts = <0x00000001 0x00000009 0x00000f04>;
			phandle = <0x00000001>;
		};
		avs-monitor@7d5d2000 {
			compatible = "brcm,bcm2711-avs-monitor", "syscon", "simple-mfd";
			reg = <0x7d5d2000 0x00000f00>;
			phandle = <0x000000c1>;
			thermal {
				compatible = "brcm,bcm2711-thermal";
				#thermal-sensor-cells = <0x00000000>;
				phandle = <0x00000002>;
			};
		};
		dma-controller@7e007000 {
			compatible = "brcm,bcm2835-dma";
			reg = <0x7e007000 0x00000b00>;
			interrupts = <0x00000000 0x00000050 0x00000004 0x00000000 0x00000051 0x00000004 0x00000000 0x00000052 0x00000004 0x00000000 0x00000053 0x00000004 0x00000000 0x00000054 0x00000004 0x00000000 0x00000055 0x00000004 0x00000000 0x00000056 0x00000004 0x00000000 0x00000057 0x00000004 0x00000000 0x00000057 0x00000004 0x00000000 0x00000058 0x00000004 0x00000000 0x00000058 0x00000004>;
			interrupt-names = "dma0", "dma1", "dma2", "dma3", "dma4", "dma5", "dma6", "dma7", "dma8", "dma9", "dma10";
			#dma-cells = <0x00000001>;
			brcm,dma-channel-mask = <0x000007f5>;
			phandle = <0x0000000c>;
		};
		watchdog@7e100000 {
			compatible = "brcm,bcm2711-pm", "brcm,bcm2835-pm-wdt";
			#power-domain-cells = <0x00000001>;
			#reset-cells = <0x00000001>;
			reg = <0x7e100000 0x00000114 0x7e00a000 0x00000024 0x7ec11000 0x00000020>;
			reg-names = "pm", "asb", "rpivid_asb";
			clocks = <0x00000008 0x00000015 0x00000008 0x0000001d 0x00000008 0x00000017 0x00000008 0x00000016>;
			clock-names = "v3d", "peri_image", "h264", "isp";
			system-power-controller;
			phandle = <0x00000049>;
		};
		rng@7e104000 {
			compatible = "brcm,bcm2711-rng200";
			reg = <0x7e104000 0x00000028>;
			status = "okay";
			phandle = <0x0000004a>;
		};
		serial@7e201400 {
			compatible = "arm,pl011", "arm,primecell";
			reg = <0x7e201400 0x00000200>;
			interrupts = <0x00000000 0x00000079 0x00000004>;
			clocks = <0x00000008 0x00000013 0x00000008 0x00000014>;
			clock-names = "uartclk", "apb_pclk";
			arm,primecell-periphid = <0x00241011>;
			status = "disabled";
			pinctrl-0 = <0x00000018>;
			pinctrl-names = "default";
			phandle = <0x000000c2>;
		};
		serial@7e201600 {
			compatible = "arm,pl011", "arm,primecell";
			reg = <0x7e201600 0x00000200>;
			interrupts = <0x00000000 0x00000079 0x00000004>;
			clocks = <0x00000008 0x00000013 0x00000008 0x00000014>;
			clock-names = "uartclk", "apb_pclk";
			arm,primecell-periphid = <0x00241011>;
			status = "disabled";
			pinctrl-0 = <0x00000019>;
			pinctrl-names = "default";
			phandle = <0x000000c3>;
		};
		serial@7e201800 {
			compatible = "arm,pl011", "arm,primecell";
			reg = <0x7e201800 0x00000200>;
			interrupts = <0x00000000 0x00000079 0x00000004>;
			clocks = <0x00000008 0x00000013 0x00000008 0x00000014>;
			clock-names = "uartclk", "apb_pclk";
			arm,primecell-periphid = <0x00241011>;
			status = "disabled";
			pinctrl-0 = <0x0000001a>;
			pinctrl-names = "default";
			phandle = <0x000000c4>;
		};
		serial@7e201a00 {
			compatible = "arm,pl011", "arm,primecell";
			reg = <0x7e201a00 0x00000200>;
			interrupts = <0x00000000 0x00000079 0x00000004>;
			clocks = <0x00000008 0x00000013 0x00000008 0x00000014>;
			clock-names = "uartclk", "apb_pclk";
			arm,primecell-periphid = <0x00241011>;
			status = "disabled";
			pinctrl-0 = <0x0000001b>;
			pinctrl-names = "default";
			phandle = <0x000000c5>;
		};
		spi@7e204600 {
			compatible = "brcm,bcm2835-spi";
			reg = <0x7e204600 0x00000200>;
			interrupts = <0x00000000 0x00000076 0x00000004>;
			clocks = <0x00000008 0x00000014>;
			#address-cells = <0x00000001>;
			#size-cells = <0x00000000>;
			status = "disabled";
			pinctrl-0 = <0x0000001c 0x0000001d>;
			pinctrl-names = "default";
			phandle = <0x000000c6>;
		};
		spi@7e204800 {
			compatible = "brcm,bcm2835-spi";
			reg = <0x7e204800 0x00000200>;
			interrupts = <0x00000000 0x00000076 0x00000004>;
			clocks = <0x00000008 0x00000014>;
			#address-cells = <0x00000001>;
			#size-cells = <0x00000000>;
			status = "disabled";
			pinctrl-0 = <0x0000001e 0x0000001f>;
			pinctrl-names = "default";
			phandle = <0x000000c7>;
		};
		spi@7e204a00 {
			compatible = "brcm,bcm2835-spi";
			reg = <0x7e204a00 0x00000200>;
			interrupts = <0x00000000 0x00000076 0x00000004>;
			clocks = <0x00000008 0x00000014>;
			#address-cells = <0x00000001>;
			#size-cells = <0x00000000>;
			status = "disabled";
			pinctrl-0 = <0x00000020 0x00000021>;
			pinctrl-names = "default";
			phandle = <0x000000c8>;
		};
		spi@7e204c00 {
			compatible = "brcm,bcm2835-spi";
			reg = <0x7e204c00 0x00000200>;
			interrupts = <0x00000000 0x00000076 0x00000004>;
			clocks = <0x00000008 0x00000014>;
			#address-cells = <0x00000001>;
			#size-cells = <0x00000000>;
			status = "disabled";
			pinctrl-0 = <0x00000022 0x00000023>;
			pinctrl-names = "default";
			phandle = <0x000000c9>;
		};
		i2c@7e205600 {
			compatible = "brcm,bcm2711-i2c", "brcm,bcm2835-i2c";
			reg = <0x7e205600 0x00000200>;
			interrupts = <0x00000000 0x00000075 0x00000004>;
			clocks = <0x00000008 0x00000014>;
			#address-cells = <0x00000001>;
			#size-cells = <0x00000000>;
			status = "disabled";
			pinctrl-0 = <0x00000024>;
			pinctrl-names = "default";
			phandle = <0x000000ca>;
		};
		i2c@7e205800 {
			compatible = "brcm,bcm2711-i2c", "brcm,bcm2835-i2c";
			reg = <0x7e205800 0x00000200>;
			interrupts = <0x00000000 0x00000075 0x00000004>;
			clocks = <0x00000008 0x00000014>;
			#address-cells = <0x00000001>;
			#size-cells = <0x00000000>;
			status = "disabled";
			pinctrl-0 = <0x00000025>;
			pinctrl-names = "default";
			phandle = <0x000000cb>;
		};
		i2c@7e205a00 {
			compatible = "brcm,bcm2711-i2c", "brcm,bcm2835-i2c";
			reg = <0x7e205a00 0x00000200>;
			interrupts = <0x00000000 0x00000075 0x00000004>;
			clocks = <0x00000008 0x00000014>;
			#address-cells = <0x00000001>;
			#size-cells = <0x00000000>;
			status = "disabled";
			pinctrl-0 = <0x00000026>;
			pinctrl-names = "default";
			phandle = <0x000000cc>;
		};
		i2c@7e205c00 {
			compatible = "brcm,bcm2711-i2c", "brcm,bcm2835-i2c";
			reg = <0x7e205c00 0x00000200>;
			interrupts = <0x00000000 0x00000075 0x00000004>;
			clocks = <0x00000008 0x00000014>;
			#address-cells = <0x00000001>;
			#size-cells = <0x00000000>;
			status = "disabled";
			pinctrl-0 = <0x00000027>;
			pinctrl-names = "default";
			phandle = <0x000000cd>;
		};
		pixelvalve@7e206000 {
			compatible = "brcm,bcm2711-pixelvalve0";
			reg = <0x7e206000 0x00000100>;
			interrupts = <0x00000000 0x0000006d 0x00000004>;
			status = "okay";
			phandle = <0x000000ce>;
		};
		pixelvalve@7e207000 {
			compatible = "brcm,bcm2711-pixelvalve1";
			reg = <0x7e207000 0x00000100>;
			interrupts = <0x00000000 0x0000006e 0x00000004>;
			status = "okay";
			phandle = <0x000000cf>;
		};
		pixelvalve@7e20a000 {
			compatible = "brcm,bcm2711-pixelvalve2";
			reg = <0x7e20a000 0x00000100>;
			interrupts = <0x00000000 0x00000065 0x00000004>;
			status = "okay";
			phandle = <0x000000d0>;
		};
		pwm@7e20c800 {
			compatible = "brcm,bcm2835-pwm";
			reg = <0x7e20c800 0x00000028>;
			clocks = <0x00000008 0x0000001e>;
			assigned-clocks = <0x00000008 0x0000001e>;
			assigned-clock-rates = <0x02faf080>;
			#pwm-cells = <0x00000003>;
			status = "disabled";
			pinctrl-names = "default";
			pinctrl-0 = <0x00000028 0x00000029>;
			phandle = <0x000000d1>;
		};
		pixelvalve@7e216000 {
			compatible = "brcm,bcm2711-pixelvalve4";
			reg = <0x7e216000 0x00000100>;
			interrupts = <0x00000000 0x0000006e 0x00000004>;
			status = "okay";
			phandle = <0x000000d2>;
		};
		pixelvalve@7ec12000 {
			compatible = "brcm,bcm2711-pixelvalve3";
			reg = <0x7ec12000 0x00000100>;
			interrupts = <0x00000000 0x0000006a 0x00000004>;
			status = "okay";
			phandle = <0x000000d3>;
		};
		vec@7ec13000 {
			compatible = "brcm,bcm2711-vec";
			reg = <0x7ec13000 0x00001000>;
			clocks = <0x00000014 0x0000000f>;
			interrupts = <0x00000000 0x0000007b 0x00000004>;
			status = "disabled";
			power-domains = <0x00000010 0x00000007>;
			phandle = <0x000000d4>;
		};
		clock@7ef00000 {
			compatible = "brcm,brcm2711-dvp";
			reg = <0x7ef00000 0x00000010>;
			clocks = <0x0000002a>;
			#clock-cells = <0x00000001>;
			#reset-cells = <0x00000001>;
			status = "okay";
			phandle = <0x0000002b>;
		};
		interrupt-controller@7ef00100 {
			compatible = "brcm,bcm2711-l2-intc", "brcm,l2-intc";
			reg = <0x7ef00100 0x00000030>;
			interrupts = <0x00000000 0x00000060 0x00000001>;
			interrupt-controller;
			#interrupt-cells = <0x00000001>;
			status = "okay";
			phandle = <0x0000002c>;
		};
		hdmi@7ef00700 {
			compatible = "brcm,bcm2711-hdmi0";
			reg = <0x7ef00700 0x00000300 0x7ef00300 0x00000200 0x7ef00f00 0x00000080 0x7ef00f80 0x00000080 0x7ef01b00 0x00000200 0x7ef01f00 0x00000400 0x7ef00200 0x00000080 0x7ef04300 0x00000100 0x7ef20000 0x00000100 0x7ef00100 0x00000030>;
			reg-names = "hdmi", "dvp", "phy", "rm", "packet", "metadata", "csc", "cec", "hd", "intr2";
			clock-names = "hdmi", "bvb", "audio", "cec";
			resets = <0x0000002b 0x00000000>;
			interrupt-parent = <0x0000002c>;
			interrupts = <0x00000000 0x00000001 0x00000002 0x00000003 0x00000004 0x00000005>;
			interrupt-names = "cec-tx", "cec-rx", "cec-low", "wakeup", "hpd-connected", "hpd-removed";
			ddc = <0x0000002d>;
			dmas = <0x0000002e 0x41fa000a>;
			dma-names = "audio-rx";
			status = "okay";
			clocks = <0x00000014 0x0000000d 0x00000014 0x0000000e 0x0000002b 0x00000000 0x0000002f>;
			wifi-2.4ghz-coexistence;
			phandle = <0x00000051>;
		};
		i2c@7ef04500 {
			compatible = "brcm,bcm2711-hdmi-i2c";
			reg = <0x7ef04500 0x00000100 0x7ef00b00 0x00000300>;
			reg-names = "bsc", "auto-i2c";
			clock-frequency = <0x00017cdc>;
			status = "okay";
			phandle = <0x0000002d>;
		};
		hdmi@7ef05700 {
			compatible = "brcm,bcm2711-hdmi1";
			reg = <0x7ef05700 0x00000300 0x7ef05300 0x00000200 0x7ef05f00 0x00000080 0x7ef05f80 0x00000080 0x7ef06b00 0x00000200 0x7ef06f00 0x00000400 0x7ef00280 0x00000080 0x7ef09300 0x00000100 0x7ef20000 0x00000100 0x7ef00100 0x00000030>;
			reg-names = "hdmi", "dvp", "phy", "rm", "packet", "metadata", "csc", "cec", "hd", "intr2";
			ddc = <0x00000030>;
			clock-names = "hdmi", "bvb", "audio", "cec";
			resets = <0x0000002b 0x00000001>;
			interrupt-parent = <0x0000002c>;
			interrupts = <0x00000008 0x00000007 0x00000006 0x00000009 0x0000000a 0x0000000b>;
			interrupt-names = "cec-tx", "cec-rx", "cec-low", "wakeup", "hpd-connected", "hpd-removed";
			dmas = <0x0000002e 0x41fa0011>;
			dma-names = "audio-rx";
			status = "okay";
			clocks = <0x00000014 0x0000000d 0x00000014 0x0000000e 0x0000002b 0x00000001 0x0000002f>;
			wifi-2.4ghz-coexistence;
			phandle = <0x00000052>;
		};
		i2c@7ef09500 {
			compatible = "brcm,bcm2711-hdmi-i2c";
			reg = <0x7ef09500 0x00000100 0x7ef05b00 0x00000300>;
			reg-names = "bsc", "auto-i2c";
			clock-frequency = <0x00017cdc>;
			status = "okay";
			phandle = <0x00000030>;
		};
		mmcnr@7e300000 {
			compatible = "brcm,bcm2835-mmc", "brcm,bcm2835-sdhci";
			reg = <0x7e300000 0x00000100>;
			interrupts = <0x00000000 0x0000007e 0x00000004>;
			clocks = <0x00000008 0x0000001c>;
			dmas = <0x0000000c 0x0000000b>;
			dma-names = "rx-tx";
			brcm,overclock-50 = <0x00000000>;
			non-removable;
			status = "okay";
			pinctrl-names = "default";
			pinctrl-0 = <0x00000031>;
			bus-width = <0x00000004>;
			phandle = <0x0000004d>;
		};
		firmwarekms@7e600000 {
			compatible = "raspberrypi,rpi-firmware-kms-2711";
			reg = <0x7e600000 0x00000100>;
			interrupts = <0x00000000 0x00000070 0x00000004>;
			brcm,firmware = <0x00000006>;
			status = "disabled";
			phandle = <0x000000d5>;
		};
		smi@7e600000 {
			compatible = "brcm,bcm2835-smi";
			reg = <0x7e600000 0x00000100>;
			interrupts = <0x00000000 0x00000070 0x00000004>;
			clocks = <0x00000008 0x0000002a>;
			assigned-clocks = <0x00000008 0x0000002a>;
			assigned-clock-rates = <0x07735940>;
			dmas = <0x0000000c 0x00000004>;
			dma-names = "rx-tx";
			status = "disabled";
			phandle = <0x000000d6>;
		};
		csi@7e800000 {
			compatible = "brcm,bcm2835-unicam";
			reg = <0x7e800000 0x00000800 0x7e802000 0x00000004>;
			interrupts = <0x00000000 0x00000066 0x00000004>;
			clocks = <0x00000008 0x0000002d 0x00000014 0x00000004>;
			clock-names = "lp", "vpu";
			power-domains = <0x00000010 0x0000000c>;
			#address-cells = <0x00000001>;
			#size-cells = <0x00000000>;
			#clock-cells = <0x00000001>;
			status = "disabled";
			phandle = <0x000000d7>;
		};
		csi@7e801000 {
			compatible = "brcm,bcm2835-unicam";
			reg = <0x7e801000 0x00000800 0x7e802004 0x00000004>;
			interrupts = <0x00000000 0x00000067 0x00000004>;
			clocks = <0x00000008 0x0000002e 0x00000014 0x00000004>;
			clock-names = "lp", "vpu";
			power-domains = <0x00000010 0x0000000d>;
			#address-cells = <0x00000001>;
			#size-cells = <0x00000000>;
			#clock-cells = <0x00000001>;
			status = "disabled";
			brcm,num-data-lanes = <0x00000002>;
			phandle = <0x000000d8>;
		};
		axiperf {
			compatible = "brcm,bcm2711-axiperf";
			reg = <0x7e009800 0x00000100 0x7ee08000 0x00000100>;
			firmware = <0x00000006>;
			status = "disabled";
			phandle = <0x0000004e>;
		};
		i2c0mux {
			compatible = "i2c-mux-pinctrl";
			#address-cells = <0x00000001>;
			#size-cells = <0x00000000>;
			i2c-parent = <0x00000032>;
			status = "disabled";
			pinctrl-names = "i2c0", "i2c_csi_dsi";
			pinctrl-0 = <0x00000033>;
			pinctrl-1 = <0x00000034>;
			phandle = <0x00000047>;
			i2c@0 {
				reg = <0x00000000>;
				#address-cells = <0x00000001>;
				#size-cells = <0x00000000>;
				phandle = <0x000000d9>;
			};
			i2c@1 {
				reg = <0x00000001>;
				#address-cells = <0x00000001>;
				#size-cells = <0x00000000>;
				phandle = <0x000000da>;
			};
		};
		firmware {
			compatible = "raspberrypi,bcm2835-firmware", "simple-mfd";
			#address-cells = <0x00000001>;
			#size-cells = <0x00000001>;
			mboxes = <0x00000035>;
			dma-ranges;
			phandle = <0x00000006>;
			clocks {
				compatible = "raspberrypi,firmware-clocks";
				#clock-cells = <0x00000001>;
				phandle = <0x00000014>;
			};
			gpio {
				compatible = "raspberrypi,firmware-gpio";
				gpio-controller;
				#gpio-cells = <0x00000002>;
				status = "okay";
				gpio-line-names = "BT_ON", "WL_ON", "PWR_LED_OFF", "GLOBAL_RESET", "VDD_SD_IO_SEL", "CAM_GPIO", "SD_PWR_ON", "SD_OC_N";
				phandle = <0x0000000b>;
			};
			reset {
				compatible = "raspberrypi,firmware-reset";
				#reset-cells = <0x00000001>;
				phandle = <0x0000003f>;
			};
			vcio {
				compatible = "raspberrypi,vcio";
				phandle = <0x000000db>;
			};
		};
		power {
			compatible = "raspberrypi,bcm2835-power";
			firmware = <0x00000006>;
			#power-domain-cells = <0x00000001>;
			phandle = <0x00000010>;
		};
		mailbox@7e00b840 {
			compatible = "brcm,bcm2711-vchiq";
			reg = <0x7e00b840 0x0000003c>;
			interrupts = <0x00000000 0x00000022 0x00000004>;
			pinctrl-names = "default";
			pinctrl-0 = <0x00000036>;
			phandle = <0x000000dc>;
		};
		gpiomem {
			compatible = "brcm,bcm2835-gpiomem";
			reg = <0x7e200000 0x00001000>;
		};
		fb {
			compatible = "brcm,bcm2708-fb";
			firmware = <0x00000006>;
			status = "disabled";
			phandle = <0x000000dd>;
		};
		sound {
			status = "disabled";
			phandle = <0x000000de>;
		};
	};
	clocks {
		clk-osc {
			compatible = "fixed-clock";
			#clock-cells = <0x00000000>;
			clock-output-names = "osc";
			clock-frequency = <0x0337f980>;
			phandle = <0x00000003>;
		};
		clk-usb {
			compatible = "fixed-clock";
			#clock-cells = <0x00000000>;
			clock-output-names = "otg";
			clock-frequency = <0x1c9c3800>;
			phandle = <0x00000016>;
		};
	};
	phy {
		compatible = "usb-nop-xceiv";
		#phy-cells = <0x00000000>;
		phandle = <0x00000017>;
	};
	gpu {
		compatible = "brcm,bcm2711-vc5";
		status = "okay";
		raspberrypi,firmware = <0x00000006>;
		phandle = <0x000000df>;
	};
	clk-27M {
		#clock-cells = <0x00000000>;
		compatible = "fixed-clock";
		clock-frequency = <0x019bfcc0>;
		clock-output-names = "27MHz-clock";
		phandle = <0x0000002f>;
	};
	clk-108M {
		#clock-cells = <0x00000000>;
		compatible = "fixed-clock";
		clock-frequency = <0x066ff300>;
		clock-output-names = "108MHz-clock";
		phandle = <0x0000002a>;
	};
	emmc2bus {
		compatible = "simple-bus";
		#address-cells = <0x00000002>;
		#size-cells = <0x00000001>;
		ranges = <0x00000000 0x7e000000 0x00000000 0xfe000000 0x01800000>;
		dma-ranges = <0x00000000 0x00000000 0x00000000 0x00000000 0xfc000000>;
		phandle = <0x000000e0>;
		mmc@7e340000 {
			compatible = "brcm,bcm2711-emmc2";
			reg = <0x00000000 0x7e340000 0x00000100>;
			interrupts = <0x00000000 0x0000007e 0x00000004>;
			clocks = <0x00000008 0x00000033>;
			status = "okay";
			vqmmc-supply = <0x00000037>;
			vmmc-supply = <0x00000038>;
			broken-cd;
			mmc-ddr-3_3v;
			phandle = <0x00000053>;
		};
	};
	arm-pmu {
		compatible = "arm,cortex-a72-pmu", "arm,armv8-pmuv3", "arm,cortex-a7-pmu";
		interrupts = <0x00000000 0x00000010 0x00000004 0x00000000 0x00000011 0x00000004 0x00000000 0x00000012 0x00000004 0x00000000 0x00000013 0x00000004>;
		interrupt-affinity = <0x00000039 0x0000003a 0x0000003b 0x0000003c>;
	};
	timer {
		compatible = "arm,armv8-timer";
		interrupts = <0x00000001 0x0000000d 0x00000f08 0x00000001 0x0000000e 0x00000f08 0x00000001 0x0000000b 0x00000f08 0x00000001 0x0000000a 0x00000f08>;
		arm,cpu-registers-not-fw-configured;
	};
	cpus {
		#address-cells = <0x00000001>;
		#size-cells = <0x00000000>;
		enable-method = "brcm,bcm2836-smp";
		phandle = <0x000000e1>;
		cpu@0 {
			device_type = "cpu";
			compatible = "arm,cortex-a72";
			reg = <0x00000000>;
			enable-method = "spin-table";
			cpu-release-addr = <0x00000000 0x000000d8>;
			d-cache-size = <0x00008000>;
			d-cache-line-size = <0x00000040>;
			d-cache-sets = <0x00000100>;
			i-cache-size = <0x0000c000>;
			i-cache-line-size = <0x00000040>;
			i-cache-sets = <0x00000100>;
			next-level-cache = <0x0000003d>;
			phandle = <0x00000039>;
		};
		cpu@1 {
			device_type = "cpu";
			compatible = "arm,cortex-a72";
			reg = <0x00000001>;
			enable-method = "spin-table";
			cpu-release-addr = <0x00000000 0x000000e0>;
			d-cache-size = <0x00008000>;
			d-cache-line-size = <0x00000040>;
			d-cache-sets = <0x00000100>;
			i-cache-size = <0x0000c000>;
			i-cache-line-size = <0x00000040>;
			i-cache-sets = <0x00000100>;
			next-level-cache = <0x0000003d>;
			phandle = <0x0000003a>;
		};
		cpu@2 {
			device_type = "cpu";
			compatible = "arm,cortex-a72";
			reg = <0x00000002>;
			enable-method = "spin-table";
			cpu-release-addr = <0x00000000 0x000000e8>;
			d-cache-size = <0x00008000>;
			d-cache-line-size = <0x00000040>;
			d-cache-sets = <0x00000100>;
			i-cache-size = <0x0000c000>;
			i-cache-line-size = <0x00000040>;
			i-cache-sets = <0x00000100>;
			next-level-cache = <0x0000003d>;
			phandle = <0x0000003b>;
		};
		cpu@3 {
			device_type = "cpu";
			compatible = "arm,cortex-a72";
			reg = <0x00000003>;
			enable-method = "spin-table";
			cpu-release-addr = <0x00000000 0x000000f0>;
			d-cache-size = <0x00008000>;
			d-cache-line-size = <0x00000040>;
			d-cache-sets = <0x00000100>;
			i-cache-size = <0x0000c000>;
			i-cache-line-size = <0x00000040>;
			i-cache-sets = <0x00000100>;
			next-level-cache = <0x0000003d>;
			phandle = <0x0000003c>;
		};
		l2-cache0 {
			compatible = "cache";
			cache-unified;
			cache-size = <0x00100000>;
			cache-line-size = <0x00000040>;
			cache-sets = <0x00000400>;
			cache-level = <0x00000002>;
			phandle = <0x0000003d>;
		};
	};
	scb {
		compatible = "simple-bus";
		#address-cells = <0x00000002>;
		#size-cells = <0x00000002>;
		ranges = <0x00000000 0x7c000000 0x00000000 0xfc000000 0x00000000 0x03800000 0x00000000 0x40000000 0x00000000 0xff800000 0x00000000 0x00800000 0x00000006 0x00000000 0x00000006 0x00000000 0x00000000 0x40000000 0x00000000 0x00000000 0x00000000 0x00000000 0x00000000 0xfc000000>;
		dma-ranges = <0x00000004 0x7c000000 0x00000000 0xfc000000 0x00000000 0x03800000 0x00000000 0x00000000 0x00000000 0x00000000 0x00000004 0x00000000>;
		phandle = <0x000000e2>;
		pcie@7d500000 {
			compatible = "brcm,bcm2711-pcie", "brcm,bcm7445-pcie";
			reg = <0x00000000 0x7d500000 0x00000000 0x00009310>;
			device_type = "pci";
			#address-cells = <0x00000003>;
			#interrupt-cells = <0x00000001>;
			#size-cells = <0x00000002>;
			interrupts = <0x00000000 0x00000093 0x00000004 0x00000000 0x00000094 0x00000004>;
			interrupt-names = "pcie", "msi";
			interrupt-map-mask = <0x00000000 0x00000000 0x00000000 0x00000007>;
			interrupt-map = <0x00000000 0x00000000 0x00000000 0x00000001 0x00000001 0x00000000 0x0000008f 0x00000004 0x00000000 0x00000000 0x00000000 0x00000002 0x00000001 0x00000000 0x00000090 0x00000004 0x00000000 0x00000000 0x00000000 0x00000003 0x00000001 0x00000000 0x00000091 0x00000004 0x00000000 0x00000000 0x00000000 0x00000004 0x00000001 0x00000000 0x00000092 0x00000004>;
			msi-controller;
			msi-parent = <0x0000003e>;
			ranges = <0x02000000 0x00000000 0xc0000000 0x00000006 0x00000000 0x00000000 0x40000000>;
			dma-ranges = <0x02000000 0x00000004 0x00000000 0x00000000 0x00000000 0x00000001 0x00000000>;
			brcm,enable-ssc;
			phandle = <0x0000003e>;
			pci@0,0 {
				device_type = "pci";
				#address-cells = <0x00000003>;
				#size-cells = <0x00000002>;
				ranges;
				reg = <0x00000000 0x00000000 0x00000000 0x00000000 0x00000000>;
				usb@0,0 {
					reg = <0x00000000 0x00000000 0x00000000 0x00000000 0x00000000>;
					resets = <0x0000003f 0x00000000>;
				};
			};
		};
		ethernet@7d580000 {
			local-mac-address = [e4 5f 01 60 b9 c2];
			compatible = "brcm,bcm2711-genet-v5";
			reg = <0x00000000 0x7d580000 0x00000000 0x00010000>;
			#address-cells = <0x00000001>;
			#size-cells = <0x00000001>;
			interrupts = <0x00000000 0x0000009d 0x00000004 0x00000000 0x0000009e 0x00000004>;
			status = "okay";
			phy-handle = <0x00000040>;
			phy-mode = "rgmii-rxid";
			phandle = <0x000000e3>;
			mdio@e14 {
				compatible = "brcm,genet-mdio-v5";
				reg = <0x00000e14 0x00000008>;
				reg-names = "mdio";
				#address-cells = <0x00000001>;
				#size-cells = <0x00000000>;
				phandle = <0x000000e4>;
				ethernet-phy@1 {
					reg = <0x00000001>;
					led-modes = <0x00000000 0x00000008>;
					phandle = <0x00000040>;
				};
			};
		};
		dma@7e007b00 {
			dma-channel-mask = <0x00003000>;
			compatible = "brcm,bcm2711-dma";
			reg = <0x00000000 0x7e007b00 0x00000000 0x00000400>;
			interrupts = <0x00000000 0x00000059 0x00000004 0x00000000 0x0000005a 0x00000004 0x00000000 0x0000005b 0x00000004 0x00000000 0x0000005c 0x00000004>;
			interrupt-names = "dma11", "dma12", "dma13", "dma14";
			#dma-cells = <0x00000001>;
			brcm,dma-channel-mask = <0x00003000>;
			phandle = <0x0000002e>;
		};
		xhci@7e9c0000 {
			compatible = "generic-xhci";
			status = "disabled";
			reg = <0x00000000 0x7e9c0000 0x00000000 0x00100000>;
			interrupts = <0x00000000 0x000000b0 0x00000004>;
			power-domains = <0x00000010 0x00000006>;
			phandle = <0x000000e5>;
		};
		codec@7eb10000 {
			compatible = "raspberrypi,rpivid-vid-decoder";
			reg = <0x00000000 0x7eb10000 0x00000000 0x00001000 0x00000000 0x7eb00000 0x00000000 0x00010000>;
			reg-names = "intc", "hevc";
			interrupts = <0x00000000 0x00000062 0x00000004>;
			clocks = <0x00000014 0x0000000b>;
			clock-names = "hevc";
		};
	};
	cam1_regulator {
		compatible = "regulator-fixed";
		regulator-name = "cam1-reg";
		enable-active-high;
		status = "okay";
		gpio = <0x0000000b 0x00000005 0x00000000>;
		phandle = <0x000000e6>;
	};
	cam1_clk {
		compatible = "fixed-clock";
		#clock-cells = <0x00000000>;
		status = "disabled";
		phandle = <0x000000e7>;
	};
	cam0_regulator {
		compatible = "regulator-fixed";
		regulator-name = "cam0-reg";
		enable-active-high;
		status = "disabled";
		phandle = <0x000000e8>;
	};
	cam0_clk {
		compatible = "fixed-clock";
		#clock-cells = <0x00000000>;
		status = "disabled";
		phandle = <0x000000e9>;
	};
	cam_dummy_reg {
		compatible = "regulator-fixed";
		regulator-name = "cam-dummy-reg";
		status = "okay";
		phandle = <0x000000ea>;
	};
	__overrides__ {
		cam0-pwdn-ctrl;
		cam0-pwdn;
		cam0-led-ctrl;
		cam0-led;
		bdaddr = [00 00 00 41 6c 6f 63 61 6c 2d 62 64 2d 61 64 64 72 65 73 73 5b 00 00 00 00 41 66 61 6c 6c 62 61 63 6b 2d 62 64 2d 61 64 64 72 65 73 73 3f 3d 30 00 00 00 00 42 6c 6f 63 61 6c 2d 62 64 2d 61 64 64 72 65 73 73 5b 00 00 00 00 42 66 61 6c 6c 62 61 63 6b 2d 62 64 2d 61 64 64 72 65 73 73 3f 3d 30 00];
		krnbt = [00 00 00 41 73 74 61 74 75 73 00];
		krnbt_baudrate = <0x00000041 0x6d61782d 0x73706565 0x643a3000 0x00000042 0x6d61782d 0x73706565 0x643a3000>;
		cache_line_size;
		uart0 = [00 00 00 43 73 74 61 74 75 73 00];
		uart1 = [00 00 00 44 73 74 61 74 75 73 00];
		i2s = [00 00 00 45 73 74 61 74 75 73 00];
		spi = [00 00 00 46 73 74 61 74 75 73 00];
		i2c0 = [00 00 00 32 73 74 61 74 75 73 00 00 00 00 47 73 74 61 74 75 73 00];
		i2c1 = [00 00 00 48 73 74 61 74 75 73 00];
		i2c = [00 00 00 48 73 74 61 74 75 73 00];
		i2c_arm = [00 00 00 48 73 74 61 74 75 73 00];
		i2c_vc = [00 00 00 32 73 74 61 74 75 73 00 00 00 00 47 73 74 61 74 75 73 00];
		i2c0_baudrate = [00 00 00 32 63 6c 6f 63 6b 2d 66 72 65 71 75 65 6e 63 79 3a 30 00];
		i2c1_baudrate = [00 00 00 48 63 6c 6f 63 6b 2d 66 72 65 71 75 65 6e 63 79 3a 30 00];
		i2c_baudrate = [00 00 00 48 63 6c 6f 63 6b 2d 66 72 65 71 75 65 6e 63 79 3a 30 00];
		i2c_arm_baudrate = [00 00 00 48 63 6c 6f 63 6b 2d 66 72 65 71 75 65 6e 63 79 3a 30 00];
		i2c_vc_baudrate = [00 00 00 32 63 6c 6f 63 6b 2d 66 72 65 71 75 65 6e 63 79 3a 30 00];
		watchdog = [00 00 00 49 73 74 61 74 75 73 00];
		random = [00 00 00 4a 73 74 61 74 75 73 00];
		sd_overclock = <0x0000004b 0x6272636d 0x2c6f7665 0x72636c6f 0x636b2d35 0x303a3000>;
		sd_force_pio = <0x0000004b 0x6272636d 0x2c666f72 0x63652d70 0x696f3f00>;
		sd_pio_limit = [00 00 00 4b 62 72 63 6d 2c 70 69 6f 2d 6c 69 6d 69 74 3a 30 00];
		sd_debug = [00 00 00 4b 62 72 63 6d 2c 64 65 62 75 67 00];
		sdio_overclock = <0x0000004c 0x6272636d 0x2c6f7665 0x72636c6f 0x636b2d35 0x303a3000 0x0000004d 0x6272636d 0x2c6f7665 0x72636c6f 0x636b2d35 0x303a3000>;
		axiperf = [00 00 00 4e 73 74 61 74 75 73 00];
		drm_fb0_vc4 = [00 00 00 4f 64 72 6d 2d 66 62 30 3d 00 2f 67 70 75 00];
		drm_fb1_vc4 = [00 00 00 4f 64 72 6d 2d 66 62 31 3d 00 2f 67 70 75 00];
		drm_fb2_vc4 = [00 00 00 4f 64 72 6d 2d 66 62 32 3d 00 2f 67 70 75 00];
		arm_freq;
		eee = [00 00 00 50 62 6f 6f 74 61 72 67 73 7b 6f 6e 3d 27 27 2c 6f 66 66 3d 27 67 65 6e 65 74 2e 65 65 65 3d 4e 27 7d 00];
		hdmi = [00 00 00 51 73 74 61 74 75 73 00 00 00 00 52 73 74 61 74 75 73 00];
		pcie = [00 00 00 3e 73 74 61 74 75 73 00];
		sd = [00 00 00 53 73 74 61 74 75 73 00];
		sd_poll_once = [00 00 00 53 6e 6f 6e 2d 72 65 6d 6f 76 61 62 6c 65 3f 00];
		spi_dma4 = <0x00000046 0x646d6173 0x3a303d00 0x0000002e 0x00000046 0x646d6173 0x3a383d00 0x0000002e>;
		i2s_dma4 = <0x00000045 0x646d6173 0x3a303d00 0x0000002e 0x00000045 0x646d6173 0x3a383d00 0x0000002e>;
		audio = [00 00 00 50 62 6f 6f 74 61 72 67 73 7b 6f 6e 3d 27 73 6e 64 5f 62 63 6d 32 38 33 35 2e 65 6e 61 62 6c 65 5f 68 65 61 64 70 68 6f 6e 65 73 3d 31 20 73 6e 64 5f 62 63 6d 32 38 33 35 2e 65 6e 61 62 6c 65 5f 68 64 6d 69 3d 31 27 2c 6f 66 66 3d 27 73 6e 64 5f 62 63 6d 32 38 33 35 2e 65 6e 61 62 6c 65 5f 68 65 61 64 70 68 6f 6e 65 73 3d 30 20 73 6e 64 5f 62 63 6d 32 38 33 35 2e 65 6e 61 62 6c 65 5f 68 64 6d 69 3d 30 27 7d 00];
		act_led_gpio = <0x00000054 0x6770696f 0x733a3400>;
		act_led_activelow = <0x00000054 0x6770696f 0x733a3800>;
		act_led_trigger = [00 00 00 54 6c 69 6e 75 78 2c 64 65 66 61 75 6c 74 2d 74 72 69 67 67 65 72 00];
		pwr_led_gpio = <0x00000055 0x6770696f 0x733a3400>;
		pwr_led_activelow = <0x00000055 0x6770696f 0x733a3800>;
		pwr_led_trigger = [00 00 00 55 6c 69 6e 75 78 2c 64 65 66 61 75 6c 74 2d 74 72 69 67 67 65 72 00];
		eth_led0 = <0x00000040 0x6c65642d 0x6d6f6465 0x733a3000>;
		eth_led1 = <0x00000040 0x6c65642d 0x6d6f6465 0x733a3400>;
	};
	memory@0 {
		device_type = "memory";
		reg = <0x00000000 0x00000000 0x30000000 0x00000000 0x40000000 0xbc000000>;
	};
	leds {
		compatible = "gpio-leds";
		phandle = <0x000000eb>;
		led-act {
			label = "ACT";
			default-state = "off";
			linux,default-trigger = "mmc0";
			gpios = <0x00000007 0x0000002a 0x00000000>;
			phandle = <0x00000054>;
		};
		led-pwr {
			label = "PWR";
			gpios = <0x0000000b 0x00000002 0x00000001>;
			default-state = "off";
			linux,default-trigger = "default-on";
			phandle = <0x00000055>;
		};
	};
	regulator-sd-io-1v8 {
		compatible = "regulator-gpio";
		regulator-name = "vdd-sd-io";
		regulator-min-microvolt = <0x001b7740>;
		regulator-max-microvolt = <0x00325aa0>;
		regulator-boot-on;
		regulator-always-on;
		regulator-settling-time-us = <0x00001388>;
		gpios = <0x0000000b 0x00000004 0x00000000>;
		states = <0x001b7740 0x00000001 0x00325aa0 0x00000000>;
		status = "okay";
		phandle = <0x00000037>;
	};
	regulator-sd-vcc {
		compatible = "regulator-fixed";
		regulator-name = "vcc-sd";
		regulator-min-microvolt = <0x00325aa0>;
		regulator-max-microvolt = <0x00325aa0>;
		regulator-boot-on;
		enable-active-high;
		gpio = <0x0000000b 0x00000006 0x00000000>;
		phandle = <0x00000038>;
	};
	fixedregulator_3v3 {
		compatible = "regulator-fixed";
		regulator-always-on;
		regulator-max-microvolt = <0x00325aa0>;
		regulator-min-microvolt = <0x00325aa0>;
		regulator-name = "3v3";
		phandle = <0x000000ec>;
	};
	fixedregulator_5v0 {
		compatible = "regulator-fixed";
		regulator-always-on;
		regulator-max-microvolt = <0x004c4b40>;
		regulator-min-microvolt = <0x004c4b40>;
		regulator-name = "5v0";
		phandle = <0x000000ed>;
	};
	zone_dma {
		#address-cells = <0x00000001>;
		#size-cells = <0x00000001>;
		dma-ranges = <0x00000000 0x00000000 0x00000000 0x40000000>;
	};
	v3dbus {
		compatible = "simple-bus";
		#address-cells = <0x00000001>;
		#size-cells = <0x00000002>;
		ranges = <0x7c500000 0x00000000 0xfc500000 0x00000000 0x03300000 0x40000000 0x00000000 0xff800000 0x00000000 0x00800000>;
		dma-ranges = <0x00000000 0x00000000 0x00000000 0x00000004 0x00000000>;
		phandle = <0x000000ee>;
		v3d@7ec04000 {
			compatible = "brcm,2711-v3d";
			reg = <0x7ec00000 0x00000000 0x00004000 0x7ec04000 0x00000000 0x00004000>;
			reg-names = "hub", "core0";
			power-domains = <0x00000049 0x00000001>;
			resets = <0x00000049 0x00000000>;
			clocks = <0x00000014 0x00000005>;
			clocks-names = "v3d";
			interrupts = <0x00000000 0x0000004a 0x00000004>;
			status = "okay";
			phandle = <0x000000ef>;
		};
	};
	__symbols__ {
		aliases = "/aliases";
		chosen = "/chosen";
		rmem = "/reserved-memory";
		cma = "/reserved-memory/linux,cma";
		blconfig = "/reserved-memory/nvram@0";
		blpubkey = "/reserved-memory/nvram@1";
		cpu_thermal = "/thermal-zones/cpu-thermal";
		thermal_trips = "/thermal-zones/cpu-thermal/trips";
		cooling_maps = "/thermal-zones/cpu-thermal/cooling-maps";
		soc = "/soc";
		system_timer = "/soc/timer@7e003000";
		txp = "/soc/txp@7e004000";
		clocks = "/soc/cprman@7e101000";
		mailbox = "/soc/mailbox@7e00b880";
		gpio = "/soc/gpio@7e200000";
		dpi_gpio0 = "/soc/gpio@7e200000/dpi-gpio0";
		emmc_gpio22 = "/soc/gpio@7e200000/emmc-gpio22";
		emmc_gpio34 = "/soc/gpio@7e200000/emmc-gpio34";
		emmc_gpio48 = "/soc/gpio@7e200000/emmc-gpio48";
		gpclk0_gpio4 = "/soc/gpio@7e200000/gpclk0-gpio4";
		gpclk1_gpio5 = "/soc/gpio@7e200000/gpclk1-gpio5";
		gpclk1_gpio42 = "/soc/gpio@7e200000/gpclk1-gpio42";
		gpclk1_gpio44 = "/soc/gpio@7e200000/gpclk1-gpio44";
		gpclk2_gpio6 = "/soc/gpio@7e200000/gpclk2-gpio6";
		gpclk2_gpio43 = "/soc/gpio@7e200000/gpclk2-gpio43";
		i2c0_gpio0 = "/soc/gpio@7e200000/i2c0if-gpio0";
		i2c0_gpio28 = "/soc/gpio@7e200000/i2c0if-gpio28";
		i2c0_gpio44 = "/soc/gpio@7e200000/i2c0if-gpio44";
		i2c1_gpio2 = "/soc/gpio@7e200000/i2c1-gpio2";
		i2c1_gpio44 = "/soc/gpio@7e200000/i2c1-gpio44";
		jtag_gpio22 = "/soc/gpio@7e200000/jtag-gpio22";
		pcm_gpio18 = "/soc/gpio@7e200000/pcm-gpio18";
		pcm_gpio28 = "/soc/gpio@7e200000/pcm-gpio28";
		sdhost_gpio48 = "/soc/gpio@7e200000/sdhost-gpio48";
		spi0_gpio7 = "/soc/gpio@7e200000/spi0-gpio7";
		spi0_gpio35 = "/soc/gpio@7e200000/spi0-gpio35";
		spi1_gpio16 = "/soc/gpio@7e200000/spi1-gpio16";
		spi2_gpio40 = "/soc/gpio@7e200000/spi2-gpio40";
		uart0_gpio14 = "/soc/gpio@7e200000/uart0-gpio14";
		uart0_ctsrts_gpio16 = "/soc/gpio@7e200000/uart0-ctsrts-gpio16";
		uart0_ctsrts_gpio30 = "/soc/gpio@7e200000/uart0-ctsrts-gpio30";
		uart0_gpio32 = "/soc/gpio@7e200000/uart0-gpio32";
		uart0_gpio36 = "/soc/gpio@7e200000/uart0-gpio36";
		uart0_ctsrts_gpio38 = "/soc/gpio@7e200000/uart0-ctsrts-gpio38";
		uart1_gpio14 = "/soc/gpio@7e200000/uart1-gpio14";
		uart1_ctsrts_gpio16 = "/soc/gpio@7e200000/uart1-ctsrts-gpio16";
		uart1_gpio32 = "/soc/gpio@7e200000/uart1-gpio32";
		uart1_ctsrts_gpio30 = "/soc/gpio@7e200000/uart1-ctsrts-gpio30";
		uart1_gpio40 = "/soc/gpio@7e200000/uart1-gpio40";
		uart1_ctsrts_gpio42 = "/soc/gpio@7e200000/uart1-ctsrts-gpio42";
		gpclk0_gpio49 = "/soc/gpio@7e200000/gpclk0-gpio49";
		gpclk1_gpio50 = "/soc/gpio@7e200000/gpclk1-gpio50";
		gpclk2_gpio51 = "/soc/gpio@7e200000/gpclk2-gpio51";
		i2c0_gpio46 = "/soc/gpio@7e200000/i2c0if-gpio46";
		i2c1_gpio46 = "/soc/gpio@7e200000/i2c1-gpio46";
		i2c3_gpio2 = "/soc/gpio@7e200000/i2c3-gpio2";
		i2c3_gpio4 = "/soc/gpio@7e200000/i2c3-gpio4";
		i2c4_gpio6 = "/soc/gpio@7e200000/i2c4-gpio6";
		i2c4_gpio8 = "/soc/gpio@7e200000/i2c4-gpio8";
		i2c5_gpio10 = "/soc/gpio@7e200000/i2c5-gpio10";
		i2c5_gpio12 = "/soc/gpio@7e200000/i2c5-gpio12";
		i2c6_gpio0 = "/soc/gpio@7e200000/i2c6-gpio0";
		i2c6_gpio22 = "/soc/gpio@7e200000/i2c6-gpio22";
		i2c_slave_gpio8 = "/soc/gpio@7e200000/i2c-slave-gpio8";
		jtag_gpio48 = "/soc/gpio@7e200000/jtag-gpio48";
		mii_gpio28 = "/soc/gpio@7e200000/mii-gpio28";
		mii_gpio36 = "/soc/gpio@7e200000/mii-gpio36";
		pcm_gpio50 = "/soc/gpio@7e200000/pcm-gpio50";
		pwm0_0_gpio12 = "/soc/gpio@7e200000/pwm0-0-gpio12";
		pwm0_0_gpio18 = "/soc/gpio@7e200000/pwm0-0-gpio18";
		pwm1_0_gpio40 = "/soc/gpio@7e200000/pwm1-0-gpio40";
		pwm0_1_gpio13 = "/soc/gpio@7e200000/pwm0-1-gpio13";
		pwm0_1_gpio19 = "/soc/gpio@7e200000/pwm0-1-gpio19";
		pwm1_1_gpio41 = "/soc/gpio@7e200000/pwm1-1-gpio41";
		pwm0_1_gpio45 = "/soc/gpio@7e200000/pwm0-1-gpio45";
		pwm0_0_gpio52 = "/soc/gpio@7e200000/pwm0-0-gpio52";
		pwm0_1_gpio53 = "/soc/gpio@7e200000/pwm0-1-gpio53";
		rgmii_gpio35 = "/soc/gpio@7e200000/rgmii-gpio35";
		rgmii_irq_gpio34 = "/soc/gpio@7e200000/rgmii-irq-gpio34";
		rgmii_irq_gpio39 = "/soc/gpio@7e200000/rgmii-irq-gpio39";
		rgmii_mdio_gpio28 = "/soc/gpio@7e200000/rgmii-mdio-gpio28";
		rgmii_mdio_gpio37 = "/soc/gpio@7e200000/rgmii-mdio-gpio37";
		spi0_gpio46 = "/soc/gpio@7e200000/spi0-gpio46";
		spi2_gpio46 = "/soc/gpio@7e200000/spi2-gpio46";
		spi3_gpio0 = "/soc/gpio@7e200000/spi3-gpio0";
		spi4_gpio4 = "/soc/gpio@7e200000/spi4-gpio4";
		spi5_gpio12 = "/soc/gpio@7e200000/spi5-gpio12";
		spi6_gpio18 = "/soc/gpio@7e200000/spi6-gpio18";
		uart2_gpio0 = "/soc/gpio@7e200000/uart2-gpio0";
		uart2_ctsrts_gpio2 = "/soc/gpio@7e200000/uart2-ctsrts-gpio2";
		uart3_gpio4 = "/soc/gpio@7e200000/uart3-gpio4";
		uart3_ctsrts_gpio6 = "/soc/gpio@7e200000/uart3-ctsrts-gpio6";
		uart4_gpio8 = "/soc/gpio@7e200000/uart4-gpio8";
		uart4_ctsrts_gpio10 = "/soc/gpio@7e200000/uart4-ctsrts-gpio10";
		uart5_gpio12 = "/soc/gpio@7e200000/uart5-gpio12";
		uart5_ctsrts_gpio14 = "/soc/gpio@7e200000/uart5-ctsrts-gpio14";
		dpi_18bit_cpadhi_gpio0 = "/soc/gpio@7e200000/dpi_18bit_cpadhi_gpio0";
		dpi_18bit_cpadhi_gpio2 = "/soc/gpio@7e200000/dpi_18bit_cpadhi_gpio2";
		dpi_18bit_gpio0 = "/soc/gpio@7e200000/dpi_18bit_gpio0";
		dpi_18bit_gpio2 = "/soc/gpio@7e200000/dpi_18bit_gpio2";
		dpi_16bit_gpio0 = "/soc/gpio@7e200000/dpi_16bit_gpio0";
		dpi_16bit_gpio2 = "/soc/gpio@7e200000/dpi_16bit_gpio2";
		dpi_16bit_cpadhi_gpio0 = "/soc/gpio@7e200000/dpi_16bit_cpadhi_gpio0";
		dpi_16bit_cpadhi_gpio2 = "/soc/gpio@7e200000/dpi_16bit_cpadhi_gpio2";
		gpioout = "/soc/gpio@7e200000/gpioout";
		alt0 = "/soc/gpio@7e200000/alt0";
		spi0_pins = "/soc/gpio@7e200000/spi0_pins";
		spi0_cs_pins = "/soc/gpio@7e200000/spi0_cs_pins";
		spi3_pins = "/soc/gpio@7e200000/spi3_pins";
		spi3_cs_pins = "/soc/gpio@7e200000/spi3_cs_pins";
		spi4_pins = "/soc/gpio@7e200000/spi4_pins";
		spi4_cs_pins = "/soc/gpio@7e200000/spi4_cs_pins";
		spi5_pins = "/soc/gpio@7e200000/spi5_pins";
		spi5_cs_pins = "/soc/gpio@7e200000/spi5_cs_pins";
		spi6_pins = "/soc/gpio@7e200000/spi6_pins";
		spi6_cs_pins = "/soc/gpio@7e200000/spi6_cs_pins";
		i2c0_pins = "/soc/gpio@7e200000/i2c0";
		i2c1_pins = "/soc/gpio@7e200000/i2c1";
		i2c3_pins = "/soc/gpio@7e200000/i2c3";
		i2c4_pins = "/soc/gpio@7e200000/i2c4";
		i2c5_pins = "/soc/gpio@7e200000/i2c5";
		i2c6_pins = "/soc/gpio@7e200000/i2c6";
		i2s_pins = "/soc/gpio@7e200000/i2s";
		sdio_pins = "/soc/gpio@7e200000/sdio_pins";
		uart2_pins = "/soc/gpio@7e200000/uart2_pins";
		uart3_pins = "/soc/gpio@7e200000/uart3_pins";
		uart4_pins = "/soc/gpio@7e200000/uart4_pins";
		uart5_pins = "/soc/gpio@7e200000/uart5_pins";
		bt_pins = "/soc/gpio@7e200000/bt_pins";
		uart0_pins = "/soc/gpio@7e200000/uart0_pins";
		uart1_pins = "/soc/gpio@7e200000/uart1_pins";
		uart1_bt_pins = "/soc/gpio@7e200000/uart1_bt_pins";
		audio_pins = "/soc/gpio@7e200000/audio_pins";
		uart0 = "/soc/serial@7e201000";
		bt = "/soc/serial@7e201000/bluetooth";
		sdhost = "/soc/mmc@7e202000";
		i2s_clk_consumer = "/soc/i2s@7e203000";
		i2s_clk_producer = "/soc/i2s@7e203000";
		i2s = "/soc/i2s@7e203000";
		spi0 = "/soc/spi@7e204000";
		spi = "/soc/spi@7e204000";
		spidev0 = "/soc/spi@7e204000/spidev@0";
		spidev1 = "/soc/spi@7e204000/spidev@1";
		i2c0if = "/soc/i2c@7e205000";
		dpi = "/soc/dpi@7e208000";
		dsi0 = "/soc/dsi@7e209000";
		aux = "/soc/aux@7e215000";
		uart1 = "/soc/serial@7e215040";
		minibt = "/soc/serial@7e215040/bluetooth";
		spi1 = "/soc/spi@7e215080";
		spi2 = "/soc/spi@7e2150c0";
		pwm = "/soc/pwm@7e20c000";
		mmc = "/soc/mmc@7e300000";
		sdhci = "/soc/mmc@7e300000";
		hvs = "/soc/hvs@7e400000";
		dsi1 = "/soc/dsi@7e700000";
		i2c_arm = "/soc/i2c@7e804000";
		i2c1 = "/soc/i2c@7e804000";
		usb = "/soc/usb@7e980000";
		local_intc = "/soc/interrupt-controller@40000000";
		gicv2 = "/soc/interrupt-controller@40041000";
		avs_monitor = "/soc/avs-monitor@7d5d2000";
		thermal = "/soc/avs-monitor@7d5d2000/thermal";
		dma = "/soc/dma-controller@7e007000";
		watchdog = "/soc/watchdog@7e100000";
		pm = "/soc/watchdog@7e100000";
		random = "/soc/rng@7e104000";
		uart2 = "/soc/serial@7e201400";
		uart3 = "/soc/serial@7e201600";
		uart4 = "/soc/serial@7e201800";
		uart5 = "/soc/serial@7e201a00";
		spi3 = "/soc/spi@7e204600";
		spi4 = "/soc/spi@7e204800";
		spi5 = "/soc/spi@7e204a00";
		spi6 = "/soc/spi@7e204c00";
		i2c3 = "/soc/i2c@7e205600";
		i2c4 = "/soc/i2c@7e205800";
		i2c5 = "/soc/i2c@7e205a00";
		i2c6 = "/soc/i2c@7e205c00";
		pixelvalve0 = "/soc/pixelvalve@7e206000";
		pixelvalve1 = "/soc/pixelvalve@7e207000";
		pixelvalve2 = "/soc/pixelvalve@7e20a000";
		pwm1 = "/soc/pwm@7e20c800";
		pixelvalve4 = "/soc/pixelvalve@7e216000";
		pixelvalve3 = "/soc/pixelvalve@7ec12000";
		vec = "/soc/vec@7ec13000";
		dvp = "/soc/clock@7ef00000";
		aon_intr = "/soc/interrupt-controller@7ef00100";
		hdmi0 = "/soc/hdmi@7ef00700";
		ddc0 = "/soc/i2c@7ef04500";
		hdmi1 = "/soc/hdmi@7ef05700";
		ddc1 = "/soc/i2c@7ef09500";
		mmcnr = "/soc/mmcnr@7e300000";
		firmwarekms = "/soc/firmwarekms@7e600000";
		smi = "/soc/smi@7e600000";
		csi0 = "/soc/csi@7e800000";
		csi1 = "/soc/csi@7e801000";
		axiperf = "/soc/axiperf";
		i2c0mux = "/soc/i2c0mux";
		i2c_csi_dsi0 = "/soc/i2c0mux/i2c@0";
		i2c_vc = "/soc/i2c0mux/i2c@0";
		i2c0 = "/soc/i2c0mux/i2c@0";
		i2c_csi_dsi = "/soc/i2c0mux/i2c@1";
		firmware = "/soc/firmware";
		firmware_clocks = "/soc/firmware/clocks";
		expgpio = "/soc/firmware/gpio";
		reset = "/soc/firmware/reset";
		vcio = "/soc/firmware/vcio";
		power = "/soc/power";
		vchiq = "/soc/mailbox@7e00b840";
		fb = "/soc/fb";
		sound = "/soc/sound";
		clk_osc = "/clocks/clk-osc";
		clk_usb = "/clocks/clk-usb";
		usbphy = "/phy";
		vc4 = "/gpu";
		clk_27MHz = "/clk-27M";
		clk_108MHz = "/clk-108M";
		emmc2bus = "/emmc2bus";
		emmc2 = "/emmc2bus/mmc@7e340000";
		cpus = "/cpus";
		cpu0 = "/cpus/cpu@0";
		cpu1 = "/cpus/cpu@1";
		cpu2 = "/cpus/cpu@2";
		cpu3 = "/cpus/cpu@3";
		l2 = "/cpus/l2-cache0";
		scb = "/scb";
		pcie0 = "/scb/pcie@7d500000";
		genet = "/scb/ethernet@7d580000";
		genet_mdio = "/scb/ethernet@7d580000/mdio@e14";
		phy1 = "/scb/ethernet@7d580000/mdio@e14/ethernet-phy@1";
		dma40 = "/scb/dma@7e007b00";
		xhci = "/scb/xhci@7e9c0000";
		cam1_reg = "/cam1_regulator";
		cam1_clk = "/cam1_clk";
		cam0_regulator = "/cam0_regulator";
		cam0_clk = "/cam0_clk";
		cam0_reg = "/cam_dummy_reg";
		cam_dummy_reg = "/cam_dummy_reg";
		leds = "/leds";
		led_act = "/leds/led-act";
		led_pwr = "/leds/led-pwr";
		sd_io_1v8_reg = "/regulator-sd-io-1v8";
		sd_vcc_reg = "/regulator-sd-vcc";
		vdd_3v3_reg = "/fixedregulator_3v3";
		vdd_5v0_reg = "/fixedregulator_5v0";
		v3dbus = "/v3dbus";
		v3d = "/v3dbus/v3d@7ec04000";
	};
};
